VERSION "dbc-export 1 2026.26.6.5"

NS_ :

BS_:

BU_: BB GTW IDB TCU TCU2 UI UIS VCSEAT2L VCSEAT2R

BO_ 1056 UIS_log: 8 UIS
 SG_ UIS_logMux M : 0|32@1+ (1,0) [0|4294967295] "" Vector__XXX
 SG_ UIS_wifiTemperature m11 : 32|32@1+ (1,0) [0|4294967295] "" Vector__XXX
 SG_ UIS_wifiStackState m12 : 32|32@1+ (1,0) [0|4294967295] "" Vector__XXX
 SG_ UIS_wifiBars m14 : 32|32@1+ (1,0) [0|4294967295] "" Vector__XXX
 SG_ UIS_wifiAutoJoinLowRSSI m15 : 32|32@1+ (1,0) [0|1] "" Vector__XXX
 SG_ UIS_valetMode m26 : 32|32@1+ (1,0) [0|1] "" Vector__XXX
 SG_ UIS_uiQtCarUptime m27 : 32|32@1+ (1,0) [0|4294967295] "" Vector__XXX
 SG_ UIS_uiMeanFPS m29 : 32|32@1+ (1,0) [0|4294967295] "" Vector__XXX
 SG_ UIS_tunerVoltageOperation m36 : 32|32@1+ (1,0) [0|4294967295] "" Vector__XXX
 SG_ UIS_tunerVoltageAntenna2 m38 : 32|32@1+ (1,0) [0|4294967295] "" Vector__XXX
 SG_ UIS_tunerVoltageAntenna1 m39 : 32|32@1+ (1,0) [0|4294967295] "" Vector__XXX
 SG_ UIS_tunerCurrentAntenna2 m44 : 32|32@1+ (1,0) [0|4294967295] "" Vector__XXX
 SG_ UIS_tunerCurrentAntenna1 m45 : 32|32@1+ (1,0) [0|4294967295] "" Vector__XXX
 SG_ UIS_tegraModemManState m62 : 32|32@1+ (1,0) [0|4294967295] "" Vector__XXX
 SG_ UIS_systemWakeTime m63 : 32|32@1+ (1,0) [0|4294967295] "" Vector__XXX
 SG_ UIS_systemUptime m64 : 32|32@1+ (1,0) [0|4294967295] "" Vector__XXX
 SG_ UIS_suspensionGeofence m66 : 32|32@1+ (1,0) [0|1] "" Vector__XXX
 SG_ UIS_superchargePaymentNeeded m67 : 32|32@1+ (1,0) [0|4294967295] "" Vector__XXX
 SG_ UIS_sleepType m79 : 32|32@1+ (1,0) [0|4294967295] "" Vector__XXX
 SG_ UIS_sleepTime m80 : 32|32@1+ (1,0) [0|4294967295] "" Vector__XXX
 SG_ UIS_sleepState m81 : 32|32@1+ (1,0) [0|4294967295] "" Vector__XXX
 SG_ UIS_slackerLoginResult m83 : 32|32@1+ (1,0) [0|4294967295] "" Vector__XXX
 SG_ UIS_sentryState m89 : 32|32@1+ (1,0) [0|4294967295] "" Vector__XXX
 SG_ UIS_sentryNeedsNap m90 : 32|32@1+ (1,0) [0|4294967295] "" Vector__XXX
 SG_ UIS_sentryIncidentCount m91 : 32|32@1+ (1,0) [0|4294967295] "" Vector__XXX
 SG_ UIS_scheduledChargingMode m92 : 32|32@1+ (1,0) [0|4294967295] "" Vector__XXX
 SG_ UIS_scheduleChargeStartTime m93 : 32|32@1+ (1,0) [0|4294967295] "" Vector__XXX
 SG_ UIS_scheduleChargeEndTime m94 : 32|32@1+ (1,0) [0|4294967295] "" Vector__XXX
 SG_ UIS_remoteRequestType m96 : 32|32@1+ (1,0) [0|4294967295] "" Vector__XXX
 SG_ UIS_rearDisplayUserPresent m99 : 32|32@1+ (1,0) [0|1] "" Vector__XXX
 SG_ UIS_rearDisplayState m100 : 32|32@1+ (1,0) [0|4294967295] "" Vector__XXX
 SG_ UIS_powerManagerState m110 : 32|5@1+ (1,0) [0|31] "" Vector__XXX
 SG_ UIS_polytopiax8664MemUsage m111 : 32|32@1+ (1,0) [0|4294967295] "" Vector__XXX
 SG_ UIS_polytopiax8664CPUUsage m112 : 32|32@1+ (1,0) [0|4294967295] "" Vector__XXX
 SG_ UIS_navServiceError m157 : 32|32@1+ (1,0) [0|4294967295] "" Vector__XXX
 SG_ UIS_navAudioVolume m158 : 32|32@1+ (1,0) [0|4294967295] "" Vector__XXX
 SG_ UIS_muteNavVolume m159 : 32|32@1+ (1,0) [0|4294967295] "" Vector__XXX
 SG_ UIS_modemECallppAvail m171 : 32|32@1+ (1,0) [0|1] "" Vector__XXX
 SG_ UIS_modemBusyActive m172 : 32|32@1+ (1,0) [0|1] "" Vector__XXX
 SG_ UIS_mirrorGeofenceActive m173 : 32|32@1+ (1,0) [0|1] "" Vector__XXX
 SG_ UIS_mediaPlaybackStatus m176 : 32|32@1+ (1,0) [0|4294967295] "" Vector__XXX
 SG_ UIS_mediaNeedAuthToken m177 : 32|32@1+ (1,0) [0|1] "" Vector__XXX
 SG_ UIS_inSuperchargerGeofence m182 : 32|32@1+ (1,0) [0|1] "" Vector__XXX
 SG_ UIS_homelinkState m184 : 32|32@1+ (1,0) [0|4294967295] "" Vector__XXX
 SG_ UIS_headsetPairResult m197 : 32|32@1+ (1,0) [0|4294967295] "" Vector__XXX
 SG_ UIS_headsetConnectionState m198 : 32|32@1+ (1,0) [0|4294967295] "" Vector__XXX
 SG_ UIS_gpsmanagerMemUsage m212 : 32|32@1+ (1,0) [0|4294967295] "" Vector__XXX
 SG_ UIS_gpsmanagerCPUUsage m213 : 32|32@1+ (1,0) [0|4294967295] "" Vector__XXX
 SG_ UIS_featureSuperchargingEnabled m221 : 32|32@1+ (1,0) [0|4294967295] "" Vector__XXX
 SG_ UIS_dmRearTouchDeviceExists m234 : 32|32@1+ (1,0) [0|4294967295] "" Vector__XXX
 SG_ UIS_dmRearPowerState m235 : 32|32@1+ (1,0) [0|1] "" Vector__XXX
 SG_ UIS_dmRearLinkCheckOk m236 : 32|32@1+ (1,0) [0|1] "" Vector__XXX
 SG_ UIS_dmRearEnabled m237 : 32|32@1+ (1,0) [0|4294967295] "" Vector__XXX
 SG_ UIS_dmRearConnected m238 : 32|32@1+ (1,0) [0|4294967295] "" Vector__XXX
 SG_ UIS_dmRearBacklightDutyCycle m242 : 32|32@1+ (1,0) [0|4294967295] "" Vector__XXX
 SG_ UIS_dmRearBacklightDevExists m243 : 32|32@1+ (1,0) [0|1] "" Vector__XXX
 SG_ UIS_dmIcuPowerState m247 : 32|32@1+ (1,0) [0|1] "" Vector__XXX
 SG_ UIS_dmIcuLinkCheckOk m248 : 32|32@1+ (1,0) [0|1] "" Vector__XXX
 SG_ UIS_dmIcuEnabled m249 : 32|32@1+ (1,0) [0|4294967295] "" Vector__XXX
 SG_ UIS_dmIcuConnected m250 : 32|32@1+ (1,0) [0|4294967295] "" Vector__XXX
 SG_ UIS_dmIcuBacklightDutyCycle m254 : 32|32@1+ (1,0) [0|4294967295] "" Vector__XXX
 SG_ UIS_dmIcuBacklightDevExists m255 : 32|32@1+ (1,0) [0|1] "" Vector__XXX
 SG_ UIS_dmGatewayLinkWedged m260 : 32|32@1+ (1,0) [0|4294967295] "" Vector__XXX
 SG_ UIS_dmCenterTouchDeviceExists m262 : 32|32@1+ (1,0) [0|4294967295] "" Vector__XXX
 SG_ UIS_dmCenterPowerState m265 : 32|32@1+ (1,0) [0|1] "" Vector__XXX
 SG_ UIS_dmCenterOsdDisplayedState m266 : 32|32@1+ (1,0) [0|1] "" Vector__XXX
 SG_ UIS_dmCenterLinkCheckOk m271 : 32|32@1+ (1,0) [0|1] "" Vector__XXX
 SG_ UIS_dmCenterEnabled m272 : 32|32@1+ (1,0) [0|4294967295] "" Vector__XXX
 SG_ UIS_dmCenterConnected m273 : 32|32@1+ (1,0) [0|4294967295] "" Vector__XXX
 SG_ UIS_dmCenterBacklightPowerLevel m274 : 32|32@1+ (1,0) [0|4294967295] "" Vector__XXX
 SG_ UIS_dmCenterBacklightDutyCycle m277 : 32|32@1+ (1,0) [0|4294967295] "" Vector__XXX
 SG_ UIS_dmCenterBacklightDevExists m278 : 32|32@1+ (1,0) [0|1] "" Vector__XXX
 SG_ UIS_dmCenterBacklightControlDefe m279 : 32|32@1+ (1,0) [0|4294967295] "" Vector__XXX
 SG_ UIS_dgpuTemperature m285 : 32|32@1+ (1,0) [0|4294967295] "" Vector__XXX
 SG_ UIS_dashcamviewerMemUsage m287 : 32|32@1+ (1,0) [0|4294967295] "" Vector__XXX
 SG_ UIS_dashcamviewerCPUUsage m288 : 32|32@1+ (1,0) [0|4294967295] "" Vector__XXX
 SG_ UIS_dashcamStorageState m294 : 32|32@1+ (1,0) [0|4294967295] "" Vector__XXX
 SG_ UIS_dashcamStorageSentryMB m295 : 32|32@1+ (1,0) [0|4294967295] "" Vector__XXX
 SG_ UIS_dashcamStorageSavedMB m296 : 32|32@1+ (1,0) [0|4294967295] "" Vector__XXX
 SG_ UIS_dashcamStorageRecentMB m297 : 32|32@1+ (1,0) [0|4294967295] "" Vector__XXX
 SG_ UIS_dashcamStorageAvailableMB m298 : 32|32@1+ (1,0) [0|4294967295] "" Vector__XXX
 SG_ UIS_dashcamState m299 : 32|32@1+ (1,0) [0|4294967295] "" Vector__XXX
 SG_ UIS_cpuTemperature m308 : 32|32@1+ (1,0) [0|4294967295] "" Vector__XXX
 SG_ UIS_clusterMemUsage m321 : 32|32@1+ (1,0) [0|4294967295] "" Vector__XXX
 SG_ UIS_clusterDisplayState m326 : 32|32@1+ (1,0) [0|4294967295] "" Vector__XXX
 SG_ UIS_clusterCPUUsage m327 : 32|32@1+ (1,0) [0|4294967295] "" Vector__XXX
 SG_ UIS_chargeOnSolarNoChargeReason m330 : 32|32@1+ (1,0) [0|4294967295] "" Vector__XXX
 SG_ UIS_chargeLocationId m331 : 32|32@1+ (1,0) [0|4294967295] "" Vector__XXX
 SG_ UIS_centerDisplayState m334 : 32|32@1+ (1,0) [0|4294967295] "" Vector__XXX
 SG_ UIS_centerDisplayEvent m335 : 32|32@1+ (1,0) [0|4294967295] "" Vector__XXX
 SG_ UIS_cellularLinkManagerState m340 : 32|32@1+ (1,0) [0|4294967295] "" Vector__XXX
 SG_ UIS_cellularConnectivityStatus m341 : 32|32@1+ (1,0) [0|1] "" Vector__XXX
 SG_ UIS_carAssistState m369 : 32|32@1+ (1,0) [0|4294967295] "" Vector__XXX
 SG_ UIS_carAssistSessionCount m370 : 32|32@1+ (1,0) [0|4294967295] "" Vector__XXX
 SG_ UIS_carAssistMicMuted m371 : 32|32@1+ (1,0) [0|1] "" Vector__XXX
 SG_ UIS_carAssistMicAlsaRms m372 : 32|32@1+ (1,0) [0|4294967295] "" Vector__XXX
 SG_ UIS_carAssistErrorCode m373 : 32|32@1+ (1,0) [0|4294967295] "" Vector__XXX
 SG_ UIS_cameraSelectableRenderState m374 : 32|32@1+ (1,0) [0|4294967295] "" Vector__XXX
 SG_ UIS_cameraSelectablePipeline m375 : 32|32@1+ (1,0) [0|4294967295] "" Vector__XXX
 SG_ UIS_cameraSelectablePacketState m376 : 32|32@1+ (1,0) [0|4294967295] "" Vector__XXX
 SG_ UIS_cameraRearViewRenderState m378 : 32|32@1+ (1,0) [0|4294967295] "" Vector__XXX
 SG_ UIS_cameraRearViewPacketState m381 : 32|32@1+ (1,0) [0|4294967295] "" Vector__XXX
 SG_ UIS_cameraRRepeaterStreamMissing m382 : 32|32@1+ (1,0) [0|1] "" Vector__XXX
 SG_ UIS_cameraRRepeaterRenderState m383 : 32|32@1+ (1,0) [0|4294967295] "" Vector__XXX
 SG_ UIS_cameraRRepeaterPopup m384 : 32|32@1+ (1,0) [0|1] "" Vector__XXX
 SG_ UIS_cameraRRepeaterPipeline m385 : 32|32@1+ (1,0) [0|4294967295] "" Vector__XXX
 SG_ UIS_cameraRRepeaterPacketState m386 : 32|32@1+ (1,0) [0|4294967295] "" Vector__XXX
 SG_ UIS_cameraRDownwardRenderState m390 : 32|32@1+ (1,0) [0|4294967295] "" Vector__XXX
 SG_ UIS_cameraRDownwardPacketState m392 : 32|32@1+ (1,0) [0|4294967295] "" Vector__XXX
 SG_ UIS_cameraLRepeaterStreamMissing m393 : 32|32@1+ (1,0) [0|1] "" Vector__XXX
 SG_ UIS_cameraLRepeaterRenderState m394 : 32|32@1+ (1,0) [0|4294967295] "" Vector__XXX
 SG_ UIS_cameraLRepeaterPopup m395 : 32|32@1+ (1,0) [0|1] "" Vector__XXX
 SG_ UIS_cameraLRepeaterPipeline m396 : 32|32@1+ (1,0) [0|4294967295] "" Vector__XXX
 SG_ UIS_cameraLRepeaterPacketState m397 : 32|32@1+ (1,0) [0|4294967295] "" Vector__XXX
 SG_ UIS_cameraLDownwardRenderState m401 : 32|32@1+ (1,0) [0|4294967295] "" Vector__XXX
 SG_ UIS_cameraLDownwardPacketState m403 : 32|32@1+ (1,0) [0|4294967295] "" Vector__XXX
 SG_ UIS_cameraFrontRenderState m405 : 32|32@1+ (1,0) [0|4294967295] "" Vector__XXX
 SG_ UIS_cameraFrontPacketState m408 : 32|32@1+ (1,0) [0|4294967295] "" Vector__XXX
 SG_ UIS_cameraBackupStreamMissing m410 : 32|32@1+ (1,0) [0|1] "" Vector__XXX
 SG_ UIS_cameraBackupRenderState m411 : 32|32@1+ (1,0) [0|4294967295] "" Vector__XXX
 SG_ UIS_cameraBackupPopup m412 : 32|32@1+ (1,0) [0|1] "" Vector__XXX
 SG_ UIS_cameraBackupPipeline m413 : 32|32@1+ (1,0) [0|4294967295] "" Vector__XXX
 SG_ UIS_cameraBackupPacketState m414 : 32|32@1+ (1,0) [0|4294967295] "" Vector__XXX
 SG_ UIS_cameraBackupFramerate m418 : 32|32@1+ (1,0) [0|4294967295] "" Vector__XXX
 SG_ UIS_boardTemperature m424 : 32|32@1+ (1,0) [0|4294967295] "" Vector__XXX
 SG_ UIS_bluetoothState m425 : 32|32@1+ (1,0) [0|4294967295] "" Vector__XXX
 SG_ UIS_bluetoothStackState m426 : 32|32@1+ (1,0) [0|4294967295] "" Vector__XXX
 SG_ UIS_bluetoothStackRearState m427 : 32|32@1+ (1,0) [0|4294967295] "" Vector__XXX
 SG_ UIS_bluetoothPairResult m428 : 32|32@1+ (1,0) [0|4294967295] "" Vector__XXX
 SG_ UIS_bluetoothMemUsage m429 : 32|32@1+ (1,0) [0|4294967295] "" Vector__XXX
 SG_ UIS_bluetoothConnectionState m430 : 32|32@1+ (1,0) [0|4294967295] "" Vector__XXX
 SG_ UIS_bluetoothCPUUsage m431 : 32|32@1+ (1,0) [0|4294967295] "" Vector__XXX
 SG_ UIS_bluetoothAutoconnectAttempts m432 : 32|32@1+ (1,0) [0|4294967295] "" Vector__XXX
 SG_ UIS_bluetoothAutoconnectActive m433 : 32|32@1+ (1,0) [0|4294967295] "" Vector__XXX
 SG_ UIS_bluetoothAutoConnectionState m434 : 32|32@1+ (1,0) [0|4294967295] "" Vector__XXX
 SG_ UIS_backlightUserRequest m439 : 32|32@1+ (1,0) [0|4294967295] "" Vector__XXX
 SG_ UIS_audioVolumeLevel m440 : 32|32@1+ (1,0) [0|4294967295] "" Vector__XXX
 SG_ UIS_audioType m441 : 32|32@1+ (1,0) [0|4294967295] "" Vector__XXX
 SG_ UIS_audioState m442 : 32|32@1+ (1,0) [0|4294967295] "" Vector__XXX
 SG_ UIS_audioSource m443 : 32|32@1+ (1,0) [0|4294967295] "" Vector__XXX
 SG_ UIS_audioPWSGain m444 : 32|32@1+ (1,0) [0|4294967295] "" Vector__XXX
 SG_ UIS_audioMediaPlaying m445 : 32|32@1+ (1,0) [0|4294967295] "" Vector__XXX
 SG_ UIS_audioMediaBrowsing m446 : 32|32@1+ (1,0) [0|4294967295] "" Vector__XXX
 SG_ UIS_audioA2BRediscoveryCount m447 : 32|32@1+ (1,0) [0|4294967295] "" Vector__XXX
 SG_ UIS_apeHardwareMinorVersion m448 : 32|32@1+ (1,0) [0|4294967295] "" Vector__XXX
 SG_ UIS_activeAppView m450 : 32|32@1+ (1,0) [0|4294967295] "" Vector__XXX
 SG_ UIS_CamViewerServiceEnabled m451 : 32|32@1+ (1,0) [0|4294967295] "" Vector__XXX

BO_ 979 UI_airbagCutoffStatus: 1 UI
 SG_ UI_airbagCutoffSwState : 0|2@1+ (1,0) [0|3] "" Vector__XXX

BO_ 1279 UI_energyConsumptionInfo: 8 UI
 SG_ UI_energyConsumptionInfoIndex M : 0|5@1+ (1,0) [0|31] "" Vector__XXX
 SG_ UI_energyLossTotal_epa m0 : 16|16@1- (1,0) [-32768|32767] "Wh" Vector__XXX
 SG_ UI_energyLossDriving_epa m0 : 32|16@1- (1,0) [-32768|32767] "Wh" Vector__XXX
 SG_ UI_energyLossClimate_epa m0 : 48|16@1- (1,0) [-32768|32767] "Wh" Vector__XXX
 SG_ UI_energyLossBattCond_epa m1 : 16|16@1- (1,0) [-32768|32767] "Wh" Vector__XXX
 SG_ UI_energyLossElevation_epa m1 : 32|16@1- (1,0) [-32768|32767] "Wh" Vector__XXX
 SG_ UI_energyLossAcc_epa m1 : 48|16@1- (1,0) [-32768|32767] "Wh" Vector__XXX
 SG_ UI_energyLossTotalSinceCharge_ep m2 : 16|16@1- (1,0) [-32768|32767] "Wh" Vector__XXX
 SG_ UI_energyLossDrivingSinceCharge_ m2 : 32|16@1- (1,0) [-32768|32767] "Wh" Vector__XXX
 SG_ UI_energyLossClimateSinceCharge_ m2 : 48|16@1- (1,0) [-32768|32767] "Wh" Vector__XXX
 SG_ UI_energyLossBattCondSinceCharge m3 : 16|16@1- (1,0) [-32768|32767] "Wh" Vector__XXX
 SG_ UI_energyLossElevationSinceCharg m3 : 32|16@1- (1,0) [-32768|32767] "Wh" Vector__XXX
 SG_ UI_energyLossAccSinceCharge_epa m3 : 48|16@1- (1,0) [-32768|32767] "Wh" Vector__XXX
 SG_ UI_energyLossTotalSinceTripStart m4 : 16|16@1- (1,0) [-32768|32767] "Wh" Vector__XXX
 SG_ UI_energyLossDrivingSinceTripSta m4 : 32|16@1- (1,0) [-32768|32767] "Wh" Vector__XXX
 SG_ UI_energyLossClimateSinceTripSta m4 : 48|16@1- (1,0) [-32768|32767] "Wh" Vector__XXX
 SG_ UI_energyLossBattCondSinceTripSt m5 : 16|16@1- (1,0) [-32768|32767] "Wh" Vector__XXX
 SG_ UI_energyLossElevationSinceTripS m5 : 32|16@1- (1,0) [-32768|32767] "Wh" Vector__XXX
 SG_ UI_energyLossAccSinceTripStart m5 : 48|16@1- (1,0) [-32768|32767] "Wh" Vector__XXX
 SG_ UI_energyDeltaTotal_epa m6 : 16|16@1- (1,0) [-32768|32767] "Wh" Vector__XXX
 SG_ UI_energyDeltaDriving_epa m6 : 32|16@1- (1,0) [-32768|32767] "Wh" Vector__XXX
 SG_ UI_energyDeltaClimate_epa m6 : 48|16@1- (1,0) [-32768|32767] "Wh" Vector__XXX
 SG_ UI_energyDeltaBattCond_epa m7 : 16|16@1- (1,0) [-32768|32767] "Wh" Vector__XXX
 SG_ UI_energyDeltaElevation_epa m7 : 32|16@1- (1,0) [-32768|32767] "Wh" Vector__XXX
 SG_ UI_energyDeltaAcc_epa m7 : 48|16@1- (1,0) [-32768|32767] "Wh" Vector__XXX
 SG_ UI_uiDeltaOffsetTotal_epa m8 : 16|16@1- (1,0) [-32768|32767] "Wh" Vector__XXX
 SG_ UI_uiDeltaOffsetDriving_epa m8 : 32|16@1- (1,0) [-32768|32767] "Wh" Vector__XXX
 SG_ UI_uiDeltaOffsetClimate_epa m8 : 48|16@1- (1,0) [-32768|32767] "Wh" Vector__XXX
 SG_ UI_uiDeltaOffsetBattCond_epa m9 : 16|16@1- (1,0) [-32768|32767] "Wh" Vector__XXX
 SG_ UI_uiDeltaOffsetElevation_epa m9 : 32|16@1- (1,0) [-32768|32767] "Wh" Vector__XXX
 SG_ UI_uiDeltaOffsetAcc_epa m9 : 48|16@1- (1,0) [-32768|32767] "Wh" Vector__XXX
 SG_ UI_rawToUiEnergyRatio_epa m10 : 8|8@1+ (0.01,0) [0|2.55] "-" Vector__XXX
 SG_ UI_driveDistance_epa m10 : 16|16@1+ (0.01,0) [0|655.35] "miles" Vector__XXX
 SG_ UI_energyDeltaTotalSinceCharge_e m11 : 16|16@1- (1,0) [-32768|32767] "Wh" Vector__XXX
 SG_ UI_energyDeltaDrivingSinceCharge m11 : 32|16@1- (1,0) [-32768|32767] "Wh" Vector__XXX
 SG_ UI_energyDeltaClimateSinceCharge m11 : 48|16@1- (1,0) [-32768|32767] "Wh" Vector__XXX
 SG_ UI_energyDeltaBattCondSinceCharg m12 : 16|16@1- (1,0) [-32768|32767] "Wh" Vector__XXX
 SG_ UI_energyDeltaElevationSinceChar m12 : 32|16@1- (1,0) [-32768|32767] "Wh" Vector__XXX
 SG_ UI_energyDeltaAccSinceCharge_epa m12 : 48|16@1- (1,0) [-32768|32767] "Wh" Vector__XXX
 SG_ UI_uiDeltaOffsetTotalSinceCharge m13 : 16|16@1- (1,0) [-32768|32767] "Wh" Vector__XXX
 SG_ UI_uiDeltaOffsetDrivingSinceChar m13 : 32|16@1- (1,0) [-32768|32767] "Wh" Vector__XXX
 SG_ UI_uiDeltaOffsetClimateSinceChar m13 : 48|16@1- (1,0) [-32768|32767] "Wh" Vector__XXX
 SG_ UI_uiDeltaOffsetBattCondSinceCha m14 : 16|16@1- (1,0) [-32768|32767] "Wh" Vector__XXX
 SG_ UI_uiDeltaOffsetElevationSinceCh m14 : 32|16@1- (1,0) [-32768|32767] "Wh" Vector__XXX
 SG_ UI_uiDeltaOffsetAccSinceCharge_e m14 : 48|16@1- (1,0) [-32768|32767] "Wh" Vector__XXX
 SG_ UI_rawToUiEnergyRatioSinceCharge m15 : 8|8@1+ (0.01,0) [0|2.55] "-" Vector__XXX
 SG_ UI_driveDistanceSinceCharge_epa m15 : 16|16@1+ (0.01,0) [0|655.35] "miles" Vector__XXX
 SG_ UI_energyDeltaTotalSinceTripStar m16 : 16|16@1- (1,0) [-32768|32767] "Wh" Vector__XXX
 SG_ UI_energyDeltaDrivingSinceTripSt m16 : 32|16@1- (1,0) [-32768|32767] "Wh" Vector__XXX
 SG_ UI_energyDeltaClimateSinceTripSt m16 : 48|16@1- (1,0) [-32768|32767] "Wh" Vector__XXX
 SG_ UI_energyDeltaBattCondSinceTripS m17 : 16|16@1- (1,0) [-32768|32767] "Wh" Vector__XXX
 SG_ UI_energyDeltaElevationSinceTrip m17 : 32|16@1- (1,0) [-32768|32767] "Wh" Vector__XXX
 SG_ UI_energyDeltaAccSinceTripStart m17 : 48|16@1- (1,0) [-32768|32767] "Wh" Vector__XXX
 SG_ UI_uiDeltaOffsetTotalSinceTripSt m18 : 16|16@1- (1,0) [-32768|32767] "Wh" Vector__XXX
 SG_ UI_uiDeltaOffsetDrivingSinceTrip m18 : 32|16@1- (1,0) [-32768|32767] "Wh" Vector__XXX
 SG_ UI_uiDeltaOffsetClimateSinceTrip m18 : 48|16@1- (1,0) [-32768|32767] "Wh" Vector__XXX
 SG_ UI_uiDeltaOffsetBattCondSinceTri m19 : 16|16@1- (1,0) [-32768|32767] "Wh" Vector__XXX
 SG_ UI_uiDeltaOffsetElevationSinceTr m19 : 32|16@1- (1,0) [-32768|32767] "Wh" Vector__XXX
 SG_ UI_uiDeltaOffsetAccSinceTripStar m19 : 48|16@1- (1,0) [-32768|32767] "Wh" Vector__XXX
 SG_ UI_rawToUiEnergyRatioSinceTripSt m20 : 8|8@1+ (0.01,0) [0|2.55] "-" Vector__XXX
 SG_ UI_driveDistanceSinceTripStart m20 : 16|16@1+ (0.01,0) [0|655.35] "miles" Vector__XXX
 SG_ UI_trailerMass m21 : 16|16@1+ (1,0) [0|65535] "kg" Vector__XXX

BO_ 666 UI_seatControl: 3 UI
 SG_ UI_seatControlIndex M : 0|2@1+ (1,0) [0|3] "" Vector__XXX
 SG_ UI_3RSeatChildLock m0 : 2|2@1+ (1,0) [0|3] "" Vector__XXX
 SG_ UI_left3RowSeatAdjustmentRequest m0 : 8|3@1+ (1,0) [0|7] "" Vector__XXX
 SG_ UI_right3RowSeatAdjustmentReques m0 : 11|3@1+ (1,0) [0|7] "" Vector__XXX
 SG_ UI_2RLeftSeatFanReq m0 : 14|2@1+ (1,0) [0|3] "" Vector__XXX
 SG_ UI_2RRightSeatFanReq m0 : 16|2@1+ (1,0) [0|3] "" Vector__XXX
 SG_ UI_seatChoreographyStopRequest m0 : 20|1@1+ (1,0) [0|1] "" Vector__XXX

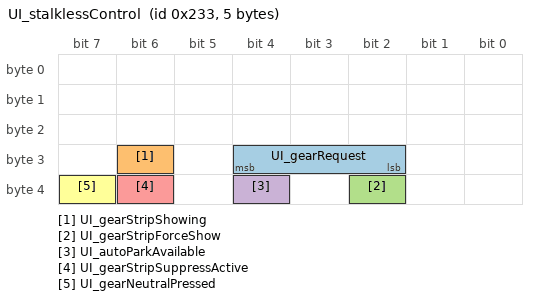
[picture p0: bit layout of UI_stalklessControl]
BO_ 563 UI_stalklessControl: 5 UI
 SG_ UI_gearRequest : 26|3@1+ (1,0) [1|7] "" Vector__XXX
 SG_ UI_gearStripShowing : 30|1@1+ (1,0) [0|1] "" Vector__XXX
 SG_ UI_gearStripForceShow : 34|1@1+ (1,0) [0|1] "" Vector__XXX
 SG_ UI_autoParkAvailable : 36|1@1+ (1,0) [0|1] "" Vector__XXX
 SG_ UI_gearStripSuppressActive : 38|1@1+ (1,0) [0|1] "" Vector__XXX
 SG_ UI_gearNeutralPressed : 39|1@1+ (1,0) [0|1] "" Vector__XXX

BO_ 986 UI_status3: 1 UI
 SG_ UI_wifiRegDomain : 0|7@1+ (1,0) [0|127] "" Vector__XXX
 SG_ UI_wifiTethered : 7|1@1+ (1,0) [0|1] "" Vector__XXX

BO_ 661 UI_systemMonitor: 8 UI
 SG_ UI_systemMonitorIndex M : 0|1@1+ (1,0) [0|1] "" Vector__XXX
 SG_ UI_SystemMemUsage m0 : 8|16@1+ (1,0) [0|65535] "MB" Vector__XXX
 SG_ UI_QtCarMemUsage m0 : 24|16@1+ (1,0) [0|65535] "MB" Vector__XXX
 SG_ UI_QtCarCPUUsage m0 : 40|7@1+ (1,0) [0|127] "%" Vector__XXX
 SG_ UI_SystemCPUUsage m0 : 48|7@1+ (1,0) [0|127] "%" Vector__XXX

BO_ 1263 UI_tripPlannerInfo: 5 UI
 SG_ UI_fwHeatOnNavArrivalSOE : 0|10@1+ (0.1,0) [0|100] "%" Vector__XXX
 SG_ UI_voyagerHeatOnNavArrivalSOE : 16|10@1+ (0.1,0) [0|100] "%" Vector__XXX

BO_ 139 UI_tripPlanning2: 6 UI
 SG_ UI_maxSpeedToReachDestination : 0|16@1+ (0.01,0) [0|655.34] "m/s" Vector__XXX
 SG_ UI_timeToDestination : 32|16@1+ (1,0) [0|65534] "s" Vector__XXX

BO_ 1173 UI_tripPlanning3: 8 UI
 SG_ UI_predictedEnergy : 0|16@1- (0.01,0) [-327.67|327.67] "kWh" Vector__XXX
 SG_ UI_hindsightEnergy : 32|16@1- (0.01,0) [-327.67|327.67] "kWh" Vector__XXX

BO_ 764 VCSEAT2L_seatStatus: 8 VCSEAT2L
 SG_ VCSEAT2L_row2SeatStatusIndex M : 0|2@1+ (1,0) [0|3] "" Vector__XXX
 SG_ VCSEAT2L_seatTrackPosReal m1 : 4|12@1- (1,0) [-2048|2047] "mm" Vector__XXX
 SG_ VCSEAT2L_seatTrackPosOffset m1 : 16|12@1- (1,0) [-2048|2047] "mm" Vector__XXX
 SG_ VCSEAT2L_seatReclineState m1 : 28|4@1+ (1,0) [0|14] "" Vector__XXX
 SG_ VCSEAT2L_seatReclineCalibrated m1 : 32|1@1+ (1,0) [0|1] "" Vector__XXX
 SG_ VCSEAT2L_seatReclinePositionStat m1 : 33|3@1+ (1,0) [0|7] "" Vector__XXX
 SG_ VCSEAT2L_seatReclineAbsPosS_0001 m1 : 36|12@1- (0.1,0) [-204.8|204.7] "deg" Vector__XXX
 SG_ VCSEAT2L_seatReclineAbsPosSwitch m1 : 48|2@1+ (1,0) [1|3] "" Vector__XXX
 SG_ VCSEAT2L_seatReclineFoldAllowed m1 : 50|1@1+ (1,0) [0|1] "" Vector__XXX
 SG_ VCSEAT2L_seatReclineUnfoldAllowe m1 : 51|1@1+ (1,0) [0|1] "" Vector__XXX
 SG_ VCSEAT2L_seatReclineAdjustmentAl m1 : 52|1@1+ (1,0) [0|1] "" Vector__XXX
 SG_ VCSEAT2L_seat1RClashAvoidanceBlo m1 : 53|3@1+ (1,0) [0|7] "" Vector__XXX
 SG_ VCSEAT2L_seat1RClashAvoidanceSta m1 : 56|2@1+ (1,0) [0|3] "" Vector__XXX
 SG_ VCSEAT2L_seatReclineChoreoBlocke m1 : 58|1@1+ (1,0) [0|1] "" Vector__XXX
 SG_ VCSEAT2L_seatReclineNextToggleDi m1 : 59|2@1+ (1,0) [0|3] "" Vector__XXX

BO_ 1986 VCSEAT2L_seatStatus2: 8 VCSEAT2L
 SG_ VCSEAT2L_seatStatus2Index M : 0|3@1+ (1,0) [0|7] "" Vector__XXX
 SG_ VCSEAT2L_choreography2RState m4 : 4|2@1+ (1,0) [0|3] "" Vector__XXX
 SG_ VCSEAT2L_choreography3RState m4 : 7|2@1+ (1,0) [0|3] "" Vector__XXX
 SG_ VCSEAT2L_choreography1RIsAllowed m4 : 10|1@1+ (1,0) [0|1] "" Vector__XXX
 SG_ VCSEAT2L_choreography2RIsAllowed m4 : 11|1@1+ (1,0) [0|1] "" Vector__XXX
 SG_ VCSEAT2L_choreography1RTrackVelo m4 : 12|3@1+ (1,0) [0|7] "" Vector__XXX
 SG_ VCSEAT2L_choreography1RBackrestV m4 : 15|3@1+ (1,0) [0|7] "" Vector__XXX
 SG_ VCSEAT2L_choreography2RTrackVelo m4 : 18|3@1+ (1,0) [0|7] "" Vector__XXX
 SG_ VCSEAT2L_choreography2RBackrestV m4 : 21|3@1+ (1,0) [0|7] "" Vector__XXX
 SG_ VCSEAT2L_choreography3RBackrestV m4 : 24|3@1+ (1,0) [0|7] "" Vector__XXX
 SG_ VCSEAT2L_choreographyState m4 : 27|4@1+ (1,0) [0|15] "" Vector__XXX
 SG_ VCSEAT2L_choreographyCollisionPa m4 : 32|3@1+ (1,0) [0|7] "" Vector__XXX
 SG_ VCSEAT2L_2rMovingForChoreography m4 : 35|1@1+ (1,0) [0|1] "" Vector__XXX

BO_ 746 VCSEAT2R_seatStatus2: 8 VCSEAT2R
 SG_ VCSEAT2R_seatStatus2Index M : 0|3@1+ (1,0) [0|7] "" Vector__XXX
 SG_ VCSEAT2R_choreography2RState m4 : 4|2@1+ (1,0) [0|3] "" Vector__XXX
 SG_ VCSEAT2R_choreography3RState m4 : 7|2@1+ (1,0) [0|3] "" Vector__XXX
 SG_ VCSEAT2R_choreography1RIsAllowed m4 : 10|1@1+ (1,0) [0|1] "" Vector__XXX
 SG_ VCSEAT2R_choreography2RIsAllowed m4 : 11|1@1+ (1,0) [0|1] "" Vector__XXX
 SG_ VCSEAT2R_choreography1RTrackVelo m4 : 12|3@1+ (1,0) [0|7] "" Vector__XXX
 SG_ VCSEAT2R_choreography1RBackrestV m4 : 15|3@1+ (1,0) [0|7] "" Vector__XXX
 SG_ VCSEAT2R_choreography2RTrackVelo m4 : 18|3@1+ (1,0) [0|7] "" Vector__XXX
 SG_ VCSEAT2R_choreography2RBackrestV m4 : 21|3@1+ (1,0) [0|7] "" Vector__XXX
 SG_ VCSEAT2R_choreography3RBackrestV m4 : 24|3@1+ (1,0) [0|7] "" Vector__XXX
 SG_ VCSEAT2R_choreographyState m4 : 27|4@1+ (1,0) [0|15] "" Vector__XXX
 SG_ VCSEAT2R_choreographyCollisionPa m4 : 32|3@1+ (1,0) [0|7] "" Vector__XXX
 SG_ VCSEAT2R_2rMovingForChoreography m4 : 35|1@1+ (1,0) [0|1] "" Vector__XXX

BO_TX_BU_ 1056 : UIS;
BO_TX_BU_ 979 : UI;
BO_TX_BU_ 1279 : UI;
BO_TX_BU_ 666 : UI;
BO_TX_BU_ 563 : UI;
BO_TX_BU_ 986 : UI;
BO_TX_BU_ 661 : UI;
BO_TX_BU_ 1263 : UI;
BO_TX_BU_ 139 : UI;
BO_TX_BU_ 1173 : UI;
BO_TX_BU_ 764 : VCSEAT2L;
BO_TX_BU_ 1986 : VCSEAT2L;
BO_TX_BU_ 746 : VCSEAT2R;
CM_ BO_ 1056 "UIS ECU message: log";
CM_ SG_ 1056 UIS_logMux "UIS ECU: log mux";
CM_ SG_ 1056 UIS_wifiTemperature "Current temperature reported for wifi";
CM_ SG_ 1056 UIS_wifiStackState "WiFi stack state description";
CM_ SG_ 1056 UIS_wifiBars "WiFi bars for connected network";
CM_ SG_ 1056 UIS_wifiAutoJoinLowRSSI "Indicates an attempt to auto-join a known network with low Received Signal Strength Indicator (RSSI).";
CM_ SG_ 1056 UIS_valetMode "UI Valet Mode state";
CM_ SG_ 1056 UIS_uiQtCarUptime "Touchscreen UI software uptime";
CM_ SG_ 1056 UIS_uiMeanFPS "UI mean frames per second over a 60s period";
CM_ SG_ 1056 UIS_tunerVoltageOperation "Radio tuner operating voltage (mV)";
CM_ SG_ 1056 UIS_tunerVoltageAntenna2 "Radio tuner voltage (mV) for antenna 2";
CM_ SG_ 1056 UIS_tunerVoltageAntenna1 "Radio tuner voltage (mV) for antenna 1";
CM_ SG_ 1056 UIS_tunerCurrentAntenna2 "Radio tuner current (mA) for antenna 2";
CM_ SG_ 1056 UIS_tunerCurrentAntenna1 "Radio tuner current (mA) for antenna 1";
CM_ SG_ 1056 UIS_tegraModemManState "Tegra Cellular Modem Manager state";
CM_ SG_ 1056 UIS_systemWakeTime "Length of time since wake or boot if UI has not slept (seconds)";
CM_ SG_ 1056 UIS_systemUptime "Reports the system uptime duration.";
CM_ SG_ 1056 UIS_suspensionGeofence "Status of suspension geofence add or remove";
CM_ SG_ 1056 UIS_superchargePaymentNeeded "Reports that Supercharging payment is needed.";
CM_ SG_ 1056 UIS_sleepType "Reports the system sleep type.";
CM_ SG_ 1056 UIS_sleepTime "Reports the system sleep duration.";
CM_ SG_ 1056 UIS_sleepState "Reports the system sleep state.";
CM_ SG_ 1056 UIS_slackerLoginResult "Reports Slacker Media login events";
CM_ SG_ 1056 UIS_sentryState "Sentry Mode state";
CM_ SG_ 1056 UIS_sentryNeedsNap "Sentry Mode sleep indicator, max uptime reached";
CM_ SG_ 1056 UIS_sentryIncidentCount "Sentry Mode incident count, initializes to 0";
CM_ SG_ 1056 UIS_scheduledChargingMode "Scheduled charging mode";
CM_ SG_ 1056 UIS_scheduleChargeStartTime "Reports the scheduled charging start date time in MMDDHHMM format.";
CM_ SG_ 1056 UIS_scheduleChargeEndTime "Reports the scheduled charging end date time in MMDDHHMM format.";
CM_ SG_ 1056 UIS_remoteRequestType "Reports the signed remote request type sent to vehicle, excluding closures and start requests.";
CM_ SG_ 1056 UIS_rearDisplayUserPresent "Indicates if a user is present in the rear seat based on seat occupancy and rear display usage";
CM_ SG_ 1056 UIS_rearDisplayState "Reports the rear display state.";
CM_ SG_ 1056 UIS_powerManagerState "UI power manager state signal; raw 18 = signal not available (SNA)";
CM_ SG_ 1056 UIS_polytopiax8664MemUsage "polytopiax8664's Resident Memory usage in MB";
CM_ SG_ 1056 UIS_polytopiax8664CPUUsage "polytopiax8664's CPU usage in CPU usage %";
CM_ SG_ 1056 UIS_navServiceError "Reports the value of the navigation service error.";
CM_ SG_ 1056 UIS_navAudioVolume "Navigation audio volume level";
CM_ SG_ 1056 UIS_muteNavVolume "Mute state of the navigation audio";
CM_ SG_ 1056 UIS_modemECallppAvail "Reports whether eCall++ is enabled and is running on Telematics Control Unit (TCU).";
CM_ SG_ 1056 UIS_modemBusyActive "Reports whether the modem busy logic is requested to be active on the modem application processor.";
CM_ SG_ 1056 UIS_mirrorGeofenceActive "Folding mirror geofence active status";
CM_ SG_ 1056 UIS_mediaPlaybackStatus "Media Current Playback Status";
CM_ SG_ 1056 UIS_mediaNeedAuthToken "Indicates whether the media system needs a new authentication token.";
CM_ SG_ 1056 UIS_inSuperchargerGeofence "Vehicle inside Supercharger Geofence";
CM_ SG_ 1056 UIS_homelinkState "State of Homelink sate machine";
CM_ SG_ 1056 UIS_headsetPairResult "Bluetooth headset pairing result";
CM_ SG_ 1056 UIS_headsetConnectionState "Bluetooth headset connection state";
CM_ SG_ 1056 UIS_gpsmanagerMemUsage "gpsManager's Resident Memory usage in MB";
CM_ SG_ 1056 UIS_gpsmanagerCPUUsage "gpsManager's CPU usage in CPU usage %";
CM_ SG_ 1056 UIS_featureSuperchargingEnabled "Reports the Supercharging enabled feature status.";
CM_ SG_ 1056 UIS_dmRearTouchDeviceExists "Reports status of rear display power state.";
CM_ SG_ 1056 UIS_dmRearPowerState "Logs rear display power state status";
CM_ SG_ 1056 UIS_dmRearLinkCheckOk "Logs whether rear display-hardware-init was successful";
CM_ SG_ 1056 UIS_dmRearEnabled "Rear display is enabled";
CM_ SG_ 1056 UIS_dmRearConnected "Rear display is connected";
CM_ SG_ 1056 UIS_dmRearBacklightDutyCycle "Logs rear backlight duty cycle status";
CM_ SG_ 1056 UIS_dmRearBacklightDevExists "Logs whether rear backlight device exists and was successfully detected";
CM_ SG_ 1056 UIS_dmIcuPowerState "Logs cluster display power state status";
CM_ SG_ 1056 UIS_dmIcuLinkCheckOk "Logs whether cluster display-hardware-init was successful";
CM_ SG_ 1056 UIS_dmIcuEnabled "Cluster display is enabled";
CM_ SG_ 1056 UIS_dmIcuConnected "Cluster display is connected";
CM_ SG_ 1056 UIS_dmIcuBacklightDutyCycle "Logs cluster backlight duty cycle status";
CM_ SG_ 1056 UIS_dmIcuBacklightDevExists "Logs whether cluster backlight device exists and was successfully detected";
CM_ SG_ 1056 UIS_dmGatewayLinkWedged "Indicates whether the center display gateway link is stuck.";
CM_ SG_ 1056 UIS_dmCenterTouchDeviceExists "Detects whether the center display touch input device is present.";
CM_ SG_ 1056 UIS_dmCenterPowerState "Logs center display power state status";
CM_ SG_ 1056 UIS_dmCenterOsdDisplayedState "Reports the center display On-Screen Display (OSD) shown state.";
CM_ SG_ 1056 UIS_dmCenterLinkCheckOk "Logs whether center display-hardware-init was successful";
CM_ SG_ 1056 UIS_dmCenterEnabled "Center display is enabled";
CM_ SG_ 1056 UIS_dmCenterConnected "Center display is connected";
CM_ SG_ 1056 UIS_dmCenterBacklightPowerLevel "Logs backlight power level for center display";
CM_ SG_ 1056 UIS_dmCenterBacklightDutyCycle "Logs center backlight duty cycle status";
CM_ SG_ 1056 UIS_dmCenterBacklightDevExists "Logs whether center backlight device exists and was successfully detected";
CM_ SG_ 1056 UIS_dmCenterBacklightControlDefe "Indicates whether the center display backlight request to the gateway was deferred to the User Datagram Protocol Application Programming Interface (UDP API) or converged within 1 second.";
CM_ SG_ 1056 UIS_dgpuTemperature "Current temperature reported for dgpu";
CM_ SG_ 1056 UIS_dashcamviewerMemUsage "dashcamViewer's Resident Memory usage in MB";
CM_ SG_ 1056 UIS_dashcamviewerCPUUsage "dashcamViewer's CPU usage in CPU usage %";
CM_ SG_ 1056 UIS_dashcamStorageState "Internal state of the dashcam storage";
CM_ SG_ 1056 UIS_dashcamStorageSentryMB "Dashcam USB storage used by Sentry Clips in MB";
CM_ SG_ 1056 UIS_dashcamStorageSavedMB "Dashcam USB storage used by Saved Clips in MB";
CM_ SG_ 1056 UIS_dashcamStorageRecentMB "Dashcam USB storage used by Recent Clips in MB";
CM_ SG_ 1056 UIS_dashcamStorageAvailableMB "Dashcam USB storage that is Available in MB";
CM_ SG_ 1056 UIS_dashcamState "Internal state for the dashcam state machine";
CM_ SG_ 1056 UIS_cpuTemperature "Current temperature reported for cpu";
CM_ SG_ 1056 UIS_clusterMemUsage "cluster's Resident Memory usage in MB";
CM_ SG_ 1056 UIS_clusterDisplayState "Reports the instrument cluster display state.";
CM_ SG_ 1056 UIS_clusterCPUUsage "cluster's CPU usage in CPU usage %";
CM_ SG_ 1056 UIS_chargeOnSolarNoChargeReason "Reason car is not charging on solar";
CM_ SG_ 1056 UIS_chargeLocationId "Privacy-respecting region identifier for charge location (1.1km accuracy, requires user consent via Software > Controls > Data Sharing)";
CM_ SG_ 1056 UIS_centerDisplayState "Reports the center display state.";
CM_ SG_ 1056 UIS_centerDisplayEvent "Reports the events that cause center display state transitions.";
CM_ SG_ 1056 UIS_cellularLinkManagerState "CellLink Manager state";
CM_ SG_ 1056 UIS_cellularConnectivityStatus "Reports the abstracted status of overall connectivity on the infotainment.";
CM_ SG_ 1056 UIS_carAssistState "Car Assist State";
CM_ SG_ 1056 UIS_carAssistSessionCount "Car Assist Session Count";
CM_ SG_ 1056 UIS_carAssistMicMuted "Reports whether the car assist microphone is muted or unmuted.";
CM_ SG_ 1056 UIS_carAssistMicAlsaRms "Monitors the car assist microphone Advanced Linux Sound Architecture (ALSA) Root Mean Squared (RMS).";
CM_ SG_ 1056 UIS_carAssistErrorCode "Car Assist Error Code";
CM_ SG_ 1056 UIS_cameraSelectableRenderState "Indicates if the touchscreen UI software has composited at least one new selectable stream camera window frame.";
CM_ SG_ 1056 UIS_cameraSelectablePipeline "Reports the selectable stream camera pipeline state.";
CM_ SG_ 1056 UIS_cameraSelectablePacketState "Indicates if Infotainment detects selectable stream camera UDP packets from Autopilot.";
CM_ SG_ 1056 UIS_cameraRearViewRenderState "Indicates if the touchscreen UI software has composited at least one new rear view camera window frame.";
CM_ SG_ 1056 UIS_cameraRearViewPacketState "Indicates if Infotainment detects rear view camera UDP packets from Autopilot.";
CM_ SG_ 1056 UIS_cameraRRepeaterStreamMissing "Signal representing if left repeater camera stream is active within videod";
CM_ SG_ 1056 UIS_cameraRRepeaterRenderState "Indicates if the touchscreen UI software has composited at least one new right repeater camera window frame.";
CM_ SG_ 1056 UIS_cameraRRepeaterPopup "Right repeater camera popup state";
CM_ SG_ 1056 UIS_cameraRRepeaterPipeline "Right repeater videod pipeline state";
CM_ SG_ 1056 UIS_cameraRRepeaterPacketState "Indicates if Infotainment detects right repeater camera UDP packets from Autopilot.";
CM_ SG_ 1056 UIS_cameraRDownwardRenderState "Indicates if the touchscreen UI software has composited at least one new right downward camera window frame.";
CM_ SG_ 1056 UIS_cameraRDownwardPacketState "Indicates if Infotainment detects right downward camera UDP packets from Autopilot.";
CM_ SG_ 1056 UIS_cameraLRepeaterStreamMissing "Signal representing if left repeater camera stream is active within videod";
CM_ SG_ 1056 UIS_cameraLRepeaterRenderState "Indicates if the touchscreen UI software has composited at least one new left repeater camera window frame.";
CM_ SG_ 1056 UIS_cameraLRepeaterPopup "Left repeater camera popup state";
CM_ SG_ 1056 UIS_cameraLRepeaterPipeline "Left repeater videod pipeline state";
CM_ SG_ 1056 UIS_cameraLRepeaterPacketState "Indicates if Infotainment detects left repeater camera UDP packets from Autopilot.";
CM_ SG_ 1056 UIS_cameraLDownwardRenderState "Indicates if the touchscreen UI software has composited at least one new left downward camera window frame.";
CM_ SG_ 1056 UIS_cameraLDownwardPacketState "Indicates if Infotainment detects left downward camera UDP packets from Autopilot.";
CM_ SG_ 1056 UIS_cameraFrontRenderState "Indicates if the touchscreen UI software has composited at least one new front fascia camera window frame.";
CM_ SG_ 1056 UIS_cameraFrontPacketState "Indicates if Infotainment detects front fascia camera UDP packets from Autopilot.";
CM_ SG_ 1056 UIS_cameraBackupStreamMissing "Signal representing if backup camera stream is active within videod";
CM_ SG_ 1056 UIS_cameraBackupRenderState "Indicates if the touchscreen UI software has composited at least one new backup camera window frame.";
CM_ SG_ 1056 UIS_cameraBackupPopup "Reports the backup camera popup state.";
CM_ SG_ 1056 UIS_cameraBackupPipeline "Reports the backup camera video pipeline state.";
CM_ SG_ 1056 UIS_cameraBackupPacketState "Indicates if Infotainment detects backup camera UDP packets from Autopilot.";
CM_ SG_ 1056 UIS_cameraBackupFramerate "Reports the backup camera framerate.";
CM_ SG_ 1056 UIS_boardTemperature "Current temperature reported for board";
CM_ SG_ 1056 UIS_bluetoothState "Reports bluetooth state.";
CM_ SG_ 1056 UIS_bluetoothStackState "Bluetooth stack state";
CM_ SG_ 1056 UIS_bluetoothStackRearState "Bluetooth rear stack state";
CM_ SG_ 1056 UIS_bluetoothPairResult "Bluetooth pairing result";
CM_ SG_ 1056 UIS_bluetoothMemUsage "Reports the Bluetooth process resident memory usage in megabytes.";
CM_ SG_ 1056 UIS_bluetoothConnectionState "Reports the Bluetooth connection state.";
CM_ SG_ 1056 UIS_bluetoothCPUUsage "Reports the Bluetooth process Central Processing Unit (CPU) usage percentage.";
CM_ SG_ 1056 UIS_bluetoothAutoconnectAttempts "Reports the number of Bluetooth auto-connect attempts for the most recent connection cycle.";
CM_ SG_ 1056 UIS_bluetoothAutoconnectActive "Indicates that Bluetooth auto-connect is active.";
CM_ SG_ 1056 UIS_bluetoothAutoConnectionState "Reports the Bluetooth auto-connection state.";
CM_ SG_ 1056 UIS_backlightUserRequest "Reports the Graphical User Interface (GUI) backlight user request value.";
CM_ SG_ 1056 UIS_audioVolumeLevel "User facing volume level";
CM_ SG_ 1056 UIS_audioType "Shows which audio amplifier type is currently configured";
CM_ SG_ 1056 UIS_audioState "Shows the state of the audio system";
CM_ SG_ 1056 UIS_audioSource "Shows which internal audio source is currently active";
CM_ SG_ 1056 UIS_audioPWSGain "Reports the pedestrian warning system volume in decibels.";
CM_ SG_ 1056 UIS_audioMediaPlaying "Shows which media source is currently being played";
CM_ SG_ 1056 UIS_audioMediaBrowsing "Shows which media source is currently being viewed";
CM_ SG_ 1056 UIS_audioA2BRediscoveryCount "Shows the count of a2b rediscoveries that have occurred";
CM_ SG_ 1056 UIS_apeHardwareMinorVersion "APE hardware minor version from device tree";
CM_ SG_ 1056 UIS_activeAppView "Shows the currently displayed app";
CM_ SG_ 1056 UIS_CamViewerServiceEnabled "Reports whether the cam-viewer service is enabled.";
CM_ BO_ 979 "Touchscreen user interface computer message: airbag cutoff status";
CM_ SG_ 979 UI_airbagCutoffSwState "Reports the front passenger airbag cutoff switch request.; raw 2 = signal not available (SNA)";
CM_ BO_ 1279 "Touchscreen user interface computer message: energy consumption info";
CM_ SG_ 1279 UI_energyConsumptionInfoIndex "Touchscreen user interface computer: energy consumption info index";
CM_ SG_ 1279 UI_energyLossTotal_epa "Energy amount for a given bucket for an energy consumption baseline (raw/real energy consumed)";
CM_ SG_ 1279 UI_energyLossDriving_epa "Energy amount for a given bucket for an energy consumption baseline (raw/real energy consumed)";
CM_ SG_ 1279 UI_energyLossClimate_epa "Energy amount for a given bucket for an energy consumption baseline (raw/real energy consumed)";
CM_ SG_ 1279 UI_energyLossBattCond_epa "Energy amount for a given bucket for an energy consumption baseline (raw/real energy consumed)";
CM_ SG_ 1279 UI_energyLossElevation_epa "Energy amount for a given bucket for an energy consumption baseline (raw/real energy consumed)";
CM_ SG_ 1279 UI_energyLossAcc_epa "Energy amount for a given bucket for an energy consumption baseline (raw/real energy consumed)";
CM_ SG_ 1279 UI_energyLossTotalSinceCharge_ep "Energy amount for a given bucket for an energy consumption baseline (raw/real energy consumed)";
CM_ SG_ 1279 UI_energyLossDrivingSinceCharge_ "Energy amount for a given bucket for an energy consumption baseline (raw/real energy consumed)";
CM_ SG_ 1279 UI_energyLossClimateSinceCharge_ "Energy amount for a given bucket for an energy consumption baseline (raw/real energy consumed)";
CM_ SG_ 1279 UI_energyLossBattCondSinceCharge "Energy amount for a given bucket for an energy consumption baseline (raw/real energy consumed)";
CM_ SG_ 1279 UI_energyLossElevationSinceCharg "Energy amount for a given bucket for an energy consumption baseline (raw/real energy consumed)";
CM_ SG_ 1279 UI_energyLossAccSinceCharge_epa "Energy amount for a given bucket for an energy consumption baseline (raw/real energy consumed)";
CM_ SG_ 1279 UI_energyLossTotalSinceTripStart "Energy amount for a given bucket for an energy consumption baseline (raw/real energy consumed)";
CM_ SG_ 1279 UI_energyLossDrivingSinceTripSta "Energy amount for a given bucket for an energy consumption baseline (raw/real energy consumed)";
CM_ SG_ 1279 UI_energyLossClimateSinceTripSta "Energy amount for a given bucket for an energy consumption baseline (raw/real energy consumed)";
CM_ SG_ 1279 UI_energyLossBattCondSinceTripSt "Energy amount for a given bucket for an energy consumption baseline (raw/real energy consumed)";
CM_ SG_ 1279 UI_energyLossElevationSinceTripS "Energy amount for a given bucket for an energy consumption baseline (raw/real energy consumed)";
CM_ SG_ 1279 UI_energyLossAccSinceTripStart "Energy amount for a given bucket for an energy consumption baseline (raw/real energy consumed)";
CM_ SG_ 1279 UI_energyDeltaTotal_epa "Energy amount for a given bucket for an energy consumption baseline (raw/real energy consumed)";
CM_ SG_ 1279 UI_energyDeltaDriving_epa "Energy amount for a given bucket for an energy consumption baseline (raw/real energy consumed)";
CM_ SG_ 1279 UI_energyDeltaClimate_epa "Energy amount for a given bucket for an energy consumption baseline (raw/real energy consumed)";
CM_ SG_ 1279 UI_energyDeltaBattCond_epa "Energy amount for a given bucket for an energy consumption baseline (raw/real energy consumed)";
CM_ SG_ 1279 UI_energyDeltaElevation_epa "Energy amount for a given bucket for an energy consumption baseline (raw/real energy consumed)";
CM_ SG_ 1279 UI_energyDeltaAcc_epa "Energy amount for a given bucket for an energy consumption baseline (raw/real energy consumed)";
CM_ SG_ 1279 UI_uiDeltaOffsetTotal_epa "Energy amount for a given bucket for an energy consumption baseline (raw/real energy consumed)";
CM_ SG_ 1279 UI_uiDeltaOffsetDriving_epa "Energy amount for a given bucket for an energy consumption baseline (raw/real energy consumed)";
CM_ SG_ 1279 UI_uiDeltaOffsetClimate_epa "Energy amount for a given bucket for an energy consumption baseline (raw/real energy consumed)";
CM_ SG_ 1279 UI_uiDeltaOffsetBattCond_epa "Energy amount for a given bucket for an energy consumption baseline (raw/real energy consumed)";
CM_ SG_ 1279 UI_uiDeltaOffsetElevation_epa "Energy amount for a given bucket for an energy consumption baseline (raw/real energy consumed)";
CM_ SG_ 1279 UI_uiDeltaOffsetAcc_epa "Energy amount for a given bucket for an energy consumption baseline (raw/real energy consumed)";
CM_ SG_ 1279 UI_rawToUiEnergyRatio_epa "Ratio used for conversion between UI and raw energy domains";
CM_ SG_ 1279 UI_driveDistance_epa "Distance driven for an energy consumption baseline";
CM_ SG_ 1279 UI_energyDeltaTotalSinceCharge_e "Energy amount for a given bucket for an energy consumption baseline (raw/real energy consumed)";
CM_ SG_ 1279 UI_energyDeltaDrivingSinceCharge "Energy amount for a given bucket for an energy consumption baseline (raw/real energy consumed)";
CM_ SG_ 1279 UI_energyDeltaClimateSinceCharge "Energy amount for a given bucket for an energy consumption baseline (raw/real energy consumed)";
CM_ SG_ 1279 UI_energyDeltaBattCondSinceCharg "Energy amount for a given bucket for an energy consumption baseline (raw/real energy consumed)";
CM_ SG_ 1279 UI_energyDeltaElevationSinceChar "Energy amount for a given bucket for an energy consumption baseline (raw/real energy consumed)";
CM_ SG_ 1279 UI_energyDeltaAccSinceCharge_epa "Energy amount for a given bucket for an energy consumption baseline (raw/real energy consumed)";
CM_ SG_ 1279 UI_uiDeltaOffsetTotalSinceCharge "Energy amount for a given bucket for an energy consumption baseline (raw/real energy consumed)";
CM_ SG_ 1279 UI_uiDeltaOffsetDrivingSinceChar "Energy amount for a given bucket for an energy consumption baseline (raw/real energy consumed)";
CM_ SG_ 1279 UI_uiDeltaOffsetClimateSinceChar "Energy amount for a given bucket for an energy consumption baseline (raw/real energy consumed)";
CM_ SG_ 1279 UI_uiDeltaOffsetBattCondSinceCha "Energy amount for a given bucket for an energy consumption baseline (raw/real energy consumed)";
CM_ SG_ 1279 UI_uiDeltaOffsetElevationSinceCh "Energy amount for a given bucket for an energy consumption baseline (raw/real energy consumed)";
CM_ SG_ 1279 UI_uiDeltaOffsetAccSinceCharge_e "Energy amount for a given bucket for an energy consumption baseline (raw/real energy consumed)";
CM_ SG_ 1279 UI_rawToUiEnergyRatioSinceCharge "Ratio used for conversion between UI and raw energy domains";
CM_ SG_ 1279 UI_driveDistanceSinceCharge_epa "Distance driven for an energy consumption baseline";
CM_ SG_ 1279 UI_energyDeltaTotalSinceTripStar "Energy amount for a given bucket for an energy consumption baseline (raw/real energy consumed)";
CM_ SG_ 1279 UI_energyDeltaDrivingSinceTripSt "Energy amount for a given bucket for an energy consumption baseline (raw/real energy consumed)";
CM_ SG_ 1279 UI_energyDeltaClimateSinceTripSt "Energy amount for a given bucket for an energy consumption baseline (raw/real energy consumed)";
CM_ SG_ 1279 UI_energyDeltaBattCondSinceTripS "Energy amount for a given bucket for an energy consumption baseline (raw/real energy consumed)";
CM_ SG_ 1279 UI_energyDeltaElevationSinceTrip "Energy amount for a given bucket for an energy consumption baseline (raw/real energy consumed)";
CM_ SG_ 1279 UI_energyDeltaAccSinceTripStart "Energy amount for a given bucket for an energy consumption baseline (raw/real energy consumed)";
CM_ SG_ 1279 UI_uiDeltaOffsetTotalSinceTripSt "Energy amount for a given bucket for an energy consumption baseline (raw/real energy consumed)";
CM_ SG_ 1279 UI_uiDeltaOffsetDrivingSinceTrip "Energy amount for a given bucket for an energy consumption baseline (raw/real energy consumed)";
CM_ SG_ 1279 UI_uiDeltaOffsetClimateSinceTrip "Energy amount for a given bucket for an energy consumption baseline (raw/real energy consumed)";
CM_ SG_ 1279 UI_uiDeltaOffsetBattCondSinceTri "Energy amount for a given bucket for an energy consumption baseline (raw/real energy consumed)";
CM_ SG_ 1279 UI_uiDeltaOffsetElevationSinceTr "Energy amount for a given bucket for an energy consumption baseline (raw/real energy consumed)";
CM_ SG_ 1279 UI_uiDeltaOffsetAccSinceTripStar "Energy amount for a given bucket for an energy consumption baseline (raw/real energy consumed)";
CM_ SG_ 1279 UI_rawToUiEnergyRatioSinceTripSt "Ratio used for conversion between UI and raw energy domains";
CM_ SG_ 1279 UI_driveDistanceSinceTripStart "Distance driven for an energy consumption baseline";
CM_ SG_ 1279 UI_trailerMass "Trailer mass from user input";
CM_ BO_ 666 "Touchscreen user interface computer message: seat control";
CM_ SG_ 666 UI_seatControlIndex "Touchscreen user interface computer: seat control index";
CM_ SG_ 666 UI_3RSeatChildLock "Reports the state of 3rd row seat fold flat child lock from the UI";
CM_ SG_ 666 UI_left3RowSeatAdjustmentRequest "Reports request from the touchscreen User Interface (UI) to actuate the left third row seat.";
CM_ SG_ 666 UI_right3RowSeatAdjustmentReques "Reports request from the touchscreen User Interface (UI) to actuate the right third row seat.";
CM_ SG_ 666 UI_2RLeftSeatFanReq "Request for second row left seat ventilation";
CM_ SG_ 666 UI_2RRightSeatFanReq "Request for second row right seat ventilation";
CM_ SG_ 666 UI_seatChoreographyStopRequest "Reports if the UI requests to stop the seat choreography";
CM_ BO_ 563 "Touchscreen user interface computer message: stalkless control";
CM_ SG_ 563 UI_gearRequest "UI gear request from UI; raw 0 = signal not available (SNA)";
CM_ SG_ 563 UI_gearStripShowing "UI communicating to GTW that the gear strip is visible on the screen as part of a handshake";
CM_ SG_ 563 UI_gearStripForceShow "UI request to GTW to show the gear strip";
CM_ SG_ 563 UI_autoParkAvailable "UI communicating to GTW that the autpark functionality is available";
CM_ SG_ 563 UI_gearStripSuppressActive "UI communicating to GTW that the gear strip should not be shown";
CM_ SG_ 563 UI_gearNeutralPressed "Neutral button is being pressed";
CM_ BO_ 986 "Touchscreen user interface computer message: status3";
CM_ SG_ 986 UI_wifiRegDomain "Indicates the Wi-Fi regulatory domain.";
CM_ SG_ 986 UI_wifiTethered "Monitors whether Wi-Fi is connected while driving.";
CM_ BO_ 661 "Touchscreen user interface computer message: system monitor";
CM_ SG_ 661 UI_systemMonitorIndex "Touchscreen user interface computer: system monitor index";
CM_ SG_ 661 UI_SystemMemUsage "Monitors system memory usage";
CM_ SG_ 661 UI_QtCarMemUsage "Monitors memory usage of the primary User Interface application";
CM_ SG_ 661 UI_QtCarCPUUsage "Monitors CPU usage of the primary User Interface application";
CM_ SG_ 661 UI_SystemCPUUsage "Monitors system CPU usage";
CM_ BO_ 1263 "Touchscreen user interface computer message: trip planner info";
CM_ SG_ 1263 UI_fwHeatOnNavArrivalSOE "Energy percentages shown in the UI";
CM_ SG_ 1263 UI_voyagerHeatOnNavArrivalSOE "Energy percentages shown in the UI";
CM_ BO_ 139 "Touchscreen user interface computer message: trip planning2";
CM_ SG_ 139 UI_maxSpeedToReachDestination "maximum speed to reach destination without significant risk of running out of energy; raw 65535 = signal not available (SNA)";
CM_ SG_ 139 UI_timeToDestination "remaining time to reach destination; raw 65535 = signal not available (SNA)";
CM_ BO_ 1173 "Touchscreen user interface computer message: trip planning3";
CM_ SG_ 1173 UI_predictedEnergy "initially predicted energy in kWh for current location along navigation route; raw 32768 = signal not available (SNA)";
CM_ SG_ 1173 UI_hindsightEnergy "hindsight energy, the model predicted energy based on measured speed and acceleration for the current location along navigation route; raw 32768 = signal not available (SNA)";
CM_ BO_ 764 "VCSEAT2L ECU message: seat status";
CM_ SG_ 764 VCSEAT2L_row2SeatStatusIndex "VCSEAT2L ECU: row2 seat status index";
CM_ SG_ 764 VCSEAT2L_seatTrackPosReal "Reports real position of seat track";
CM_ SG_ 764 VCSEAT2L_seatTrackPosOffset "VCSEAT2L ECU: seat track pos offset";
CM_ SG_ 764 VCSEAT2L_seatReclineState "Reports the active state of the 2nd row seat recliner; raw 15 = signal not available (SNA)";
CM_ SG_ 764 VCSEAT2L_seatReclineCalibrated "Reports calibration status of the 2nd row seat recliner";
CM_ SG_ 764 VCSEAT2L_seatReclinePositionStat "Reports the active position state of the 2nd row seat recliner; raw 4 = signal not available (SNA)";
CM_ SG_ 764 VCSEAT2L_seatReclineAbsPosS_0001 "VCSEAT2L ECU: seat recline abs pos switch trans point";
CM_ SG_ 764 VCSEAT2L_seatReclineAbsPosSwitch "Reports the status of 2nd row seat recline absolute position (comfort zone) switch; raw 0 = signal not available (SNA)";
CM_ SG_ 764 VCSEAT2L_seatReclineFoldAllowed "VCSEAT2L ECU: seat recline fold allowed";
CM_ SG_ 764 VCSEAT2L_seatReclineUnfoldAllowe "VCSEAT2L ECU: seat recline unfold allowed";
CM_ SG_ 764 VCSEAT2L_seatReclineAdjustmentAl "VCSEAT2L ECU: seat recline adjustment allowed";
CM_ SG_ 764 VCSEAT2L_seat1RClashAvoidanceBlo "VCSEAT2L ECU: seat1 r clash avoidance blocked reason";
CM_ SG_ 764 VCSEAT2L_seat1RClashAvoidanceSta "VCSEAT2L ECU: seat1 r clash avoidance state";
CM_ SG_ 764 VCSEAT2L_seatReclineChoreoBlocke "VCSEAT2L ECU: seat recline choreo blocked by occupancy";
CM_ SG_ 764 VCSEAT2L_seatReclineNextToggleDi "VCSEAT2L ECU: seat recline next toggle direction; raw 2 = signal not available (SNA)";
CM_ BO_ 1986 "VCSEAT2L ECU message: seat status2";
CM_ SG_ 1986 VCSEAT2L_seatStatus2Index "VCSEAT2L ECU: seat status2 index";
CM_ SG_ 1986 VCSEAT2L_choreography2RState "VCSEAT2L ECU: choreography2 r state";
CM_ SG_ 1986 VCSEAT2L_choreography3RState "VCSEAT2L ECU: choreography3 r state";
CM_ SG_ 1986 VCSEAT2L_choreography1RIsAllowed "VCSEAT2L ECU: choreography1 r is allowed to move";
CM_ SG_ 1986 VCSEAT2L_choreography2RIsAllowed "VCSEAT2L ECU: choreography2 r is allowed to move";
CM_ SG_ 1986 VCSEAT2L_choreography1RTrackVelo "VCSEAT2L ECU: choreography1 r track velocity type";
CM_ SG_ 1986 VCSEAT2L_choreography1RBackrestV "VCSEAT2L ECU: choreography1 r backrest velocity type";
CM_ SG_ 1986 VCSEAT2L_choreography2RTrackVelo "VCSEAT2L ECU: choreography2 r track velocity type";
CM_ SG_ 1986 VCSEAT2L_choreography2RBackrestV "VCSEAT2L ECU: choreography2 r backrest velocity type";
CM_ SG_ 1986 VCSEAT2L_choreography3RBackrestV "VCSEAT2L ECU: choreography3 r backrest velocity type";
CM_ SG_ 1986 VCSEAT2L_choreographyState "VCSEAT2L ECU: choreography state";
CM_ SG_ 1986 VCSEAT2L_choreographyCollisionPa "VCSEAT2L ECU: choreography collision pair";
CM_ SG_ 1986 VCSEAT2L_2rMovingForChoreography "VCSEAT2L ECU: 2r moving for choreography";
CM_ BO_ 746 "VCSEAT2R ECU message: seat status2";
CM_ SG_ 746 VCSEAT2R_seatStatus2Index "VCSEAT2R ECU: seat status2 index";
CM_ SG_ 746 VCSEAT2R_choreography2RState "VCSEAT2R ECU: choreography2 r state";
CM_ SG_ 746 VCSEAT2R_choreography3RState "VCSEAT2R ECU: choreography3 r state";
CM_ SG_ 746 VCSEAT2R_choreography1RIsAllowed "VCSEAT2R ECU: choreography1 r is allowed to move";
CM_ SG_ 746 VCSEAT2R_choreography2RIsAllowed "VCSEAT2R ECU: choreography2 r is allowed to move";
CM_ SG_ 746 VCSEAT2R_choreography1RTrackVelo "VCSEAT2R ECU: choreography1 r track velocity type";
CM_ SG_ 746 VCSEAT2R_choreography1RBackrestV "VCSEAT2R ECU: choreography1 r backrest velocity type";
CM_ SG_ 746 VCSEAT2R_choreography2RTrackVelo "VCSEAT2R ECU: choreography2 r track velocity type";
CM_ SG_ 746 VCSEAT2R_choreography2RBackrestV "VCSEAT2R ECU: choreography2 r backrest velocity type";
CM_ SG_ 746 VCSEAT2R_choreography3RBackrestV "VCSEAT2R ECU: choreography3 r backrest velocity type";
CM_ SG_ 746 VCSEAT2R_choreographyState "VCSEAT2R ECU: choreography state";
CM_ SG_ 746 VCSEAT2R_choreographyCollisionPa "VCSEAT2R ECU: choreography collision pair";
CM_ SG_ 746 VCSEAT2R_2rMovingForChoreography "VCSEAT2R ECU: 2r moving for choreography";
BA_DEF_ BO_ "GenMsgCycleTime" INT 0 3600000;
BA_DEF_ BO_ "GenMsgSendType" ENUM "Cyclic","NotUsed","NotUsed","NotUsed","NotUsed","NotUsed","NotUsed","IfActive","NoMsgSendType","NotUsed";
BA_DEF_ BO_ "VFrameFormat" ENUM "StandardCAN","ExtendedCAN","reserved","J1939PG","reserved","reserved","reserved","reserved","reserved","reserved","reserved","reserved","reserved","reserved","StandardCAN_FD","ExtendedCAN_FD";
BA_DEF_ BO_ "CANFD_BRS" ENUM "0","1";
BA_DEF_ SG_ "GenSigSNA" STRING;
BA_DEF_ SG_ "SystemSignalLongSymbol" STRING;
BA_DEF_ SG_ "Confidence" ENUM "validated","plausible","layout-only","contradicted";
BA_DEF_DEF_ "GenMsgCycleTime" 0;
BA_DEF_DEF_ "GenMsgSendType" "NoMsgSendType";
BA_DEF_DEF_ "VFrameFormat" "StandardCAN";
BA_DEF_DEF_ "CANFD_BRS" "1";
BA_DEF_DEF_ "GenSigSNA" "";
BA_DEF_DEF_ "SystemSignalLongSymbol" "";
BA_DEF_DEF_ "Confidence" "layout-only";
BA_ "GenMsgCycleTime" BO_ 979 500;
BA_ "GenMsgSendType" BO_ 979 0;
BA_ "GenMsgCycleTime" BO_ 1279 1000;
BA_ "GenMsgSendType" BO_ 1279 0;
BA_ "GenMsgCycleTime" BO_ 666 500;
BA_ "GenMsgSendType" BO_ 666 0;
BA_ "GenMsgCycleTime" BO_ 563 500;
BA_ "GenMsgSendType" BO_ 563 0;
BA_ "GenMsgCycleTime" BO_ 986 1000;
BA_ "GenMsgSendType" BO_ 986 0;
BA_ "GenMsgCycleTime" BO_ 661 15000;
BA_ "GenMsgSendType" BO_ 661 0;
BA_ "GenMsgCycleTime" BO_ 1263 1000;
BA_ "GenMsgSendType" BO_ 1263 0;
BA_ "GenMsgCycleTime" BO_ 139 1000;
BA_ "GenMsgSendType" BO_ 139 0;
BA_ "GenMsgCycleTime" BO_ 1173 1000;
BA_ "GenMsgSendType" BO_ 1173 0;
BA_ "GenMsgCycleTime" BO_ 764 100;
BA_ "GenMsgSendType" BO_ 764 0;
BA_ "GenMsgCycleTime" BO_ 1986 200;
BA_ "GenMsgSendType" BO_ 1986 0;
BA_ "GenMsgCycleTime" BO_ 746 200;
BA_ "GenMsgSendType" BO_ 746 0;
BA_ "Confidence" SG_ 1056 UIS_logMux 1;
BA_ "Confidence" SG_ 1056 UIS_wifiTemperature 0;
BA_ "Confidence" SG_ 1056 UIS_wifiStackState 0;
BA_ "Confidence" SG_ 1056 UIS_wifiBars 0;
BA_ "Confidence" SG_ 1056 UIS_wifiAutoJoinLowRSSI 0;
BA_ "Confidence" SG_ 1056 UIS_valetMode 0;
BA_ "Confidence" SG_ 1056 UIS_uiQtCarUptime 0;
BA_ "Confidence" SG_ 1056 UIS_uiMeanFPS 0;
BA_ "Confidence" SG_ 1056 UIS_tunerVoltageOperation 0;
BA_ "Confidence" SG_ 1056 UIS_tunerVoltageAntenna2 0;
BA_ "Confidence" SG_ 1056 UIS_tunerVoltageAntenna1 0;
BA_ "Confidence" SG_ 1056 UIS_tunerCurrentAntenna2 0;
BA_ "Confidence" SG_ 1056 UIS_tunerCurrentAntenna1 0;
BA_ "Confidence" SG_ 1056 UIS_tegraModemManState 0;
BA_ "Confidence" SG_ 1056 UIS_systemWakeTime 0;
BA_ "Confidence" SG_ 1056 UIS_systemUptime 0;
BA_ "Confidence" SG_ 1056 UIS_suspensionGeofence 0;
BA_ "Confidence" SG_ 1056 UIS_superchargePaymentNeeded 0;
BA_ "Confidence" SG_ 1056 UIS_sleepType 0;
BA_ "Confidence" SG_ 1056 UIS_sleepTime 0;
BA_ "Confidence" SG_ 1056 UIS_sleepState 0;
BA_ "Confidence" SG_ 1056 UIS_slackerLoginResult 0;
BA_ "Confidence" SG_ 1056 UIS_sentryState 0;
BA_ "Confidence" SG_ 1056 UIS_sentryNeedsNap 0;
BA_ "Confidence" SG_ 1056 UIS_sentryIncidentCount 0;
BA_ "Confidence" SG_ 1056 UIS_scheduledChargingMode 0;
BA_ "Confidence" SG_ 1056 UIS_scheduleChargeStartTime 0;
BA_ "Confidence" SG_ 1056 UIS_scheduleChargeEndTime 0;
BA_ "Confidence" SG_ 1056 UIS_remoteRequestType 0;
BA_ "Confidence" SG_ 1056 UIS_rearDisplayUserPresent 0;
BA_ "Confidence" SG_ 1056 UIS_rearDisplayState 0;
BA_ "Confidence" SG_ 1056 UIS_powerManagerState 0;
BA_ "GenSigSNA" SG_ 1056 UIS_powerManagerState "18";
BA_ "Confidence" SG_ 1056 UIS_polytopiax8664MemUsage 0;
BA_ "Confidence" SG_ 1056 UIS_polytopiax8664CPUUsage 0;
BA_ "Confidence" SG_ 1056 UIS_navServiceError 0;
BA_ "Confidence" SG_ 1056 UIS_navAudioVolume 0;
BA_ "Confidence" SG_ 1056 UIS_muteNavVolume 0;
BA_ "Confidence" SG_ 1056 UIS_modemECallppAvail 0;
BA_ "Confidence" SG_ 1056 UIS_modemBusyActive 0;
BA_ "Confidence" SG_ 1056 UIS_mirrorGeofenceActive 0;
BA_ "Confidence" SG_ 1056 UIS_mediaPlaybackStatus 0;
BA_ "Confidence" SG_ 1056 UIS_mediaNeedAuthToken 0;
BA_ "Confidence" SG_ 1056 UIS_inSuperchargerGeofence 0;
BA_ "Confidence" SG_ 1056 UIS_homelinkState 0;
BA_ "Confidence" SG_ 1056 UIS_headsetPairResult 0;
BA_ "Confidence" SG_ 1056 UIS_headsetConnectionState 0;
BA_ "Confidence" SG_ 1056 UIS_gpsmanagerMemUsage 0;
BA_ "Confidence" SG_ 1056 UIS_gpsmanagerCPUUsage 0;
BA_ "Confidence" SG_ 1056 UIS_featureSuperchargingEnabled 0;
BA_ "Confidence" SG_ 1056 UIS_dmRearTouchDeviceExists 0;
BA_ "Confidence" SG_ 1056 UIS_dmRearPowerState 0;
BA_ "Confidence" SG_ 1056 UIS_dmRearLinkCheckOk 0;
BA_ "Confidence" SG_ 1056 UIS_dmRearEnabled 0;
BA_ "Confidence" SG_ 1056 UIS_dmRearConnected 0;
BA_ "Confidence" SG_ 1056 UIS_dmRearBacklightDutyCycle 0;
BA_ "Confidence" SG_ 1056 UIS_dmRearBacklightDevExists 0;
BA_ "Confidence" SG_ 1056 UIS_dmIcuPowerState 0;
BA_ "Confidence" SG_ 1056 UIS_dmIcuLinkCheckOk 0;
BA_ "Confidence" SG_ 1056 UIS_dmIcuEnabled 0;
BA_ "Confidence" SG_ 1056 UIS_dmIcuConnected 0;
BA_ "Confidence" SG_ 1056 UIS_dmIcuBacklightDutyCycle 0;
BA_ "Confidence" SG_ 1056 UIS_dmIcuBacklightDevExists 0;
BA_ "Confidence" SG_ 1056 UIS_dmGatewayLinkWedged 0;
BA_ "Confidence" SG_ 1056 UIS_dmCenterTouchDeviceExists 0;
BA_ "Confidence" SG_ 1056 UIS_dmCenterPowerState 0;
BA_ "Confidence" SG_ 1056 UIS_dmCenterOsdDisplayedState 0;
BA_ "Confidence" SG_ 1056 UIS_dmCenterLinkCheckOk 0;
BA_ "Confidence" SG_ 1056 UIS_dmCenterEnabled 0;
BA_ "Confidence" SG_ 1056 UIS_dmCenterConnected 0;
BA_ "Confidence" SG_ 1056 UIS_dmCenterBacklightPowerLevel 0;
BA_ "Confidence" SG_ 1056 UIS_dmCenterBacklightDutyCycle 0;
BA_ "Confidence" SG_ 1056 UIS_dmCenterBacklightDevExists 0;
BA_ "Confidence" SG_ 1056 UIS_dmCenterBacklightControlDefe 0;
BA_ "SystemSignalLongSymbol" SG_ 1056 UIS_dmCenterBacklightControlDefe "UIS_dmCenterBacklightControlDeferred";
BA_ "Confidence" SG_ 1056 UIS_dgpuTemperature 0;
BA_ "Confidence" SG_ 1056 UIS_dashcamviewerMemUsage 0;
BA_ "Confidence" SG_ 1056 UIS_dashcamviewerCPUUsage 0;
BA_ "Confidence" SG_ 1056 UIS_dashcamStorageState 0;
BA_ "Confidence" SG_ 1056 UIS_dashcamStorageSentryMB 0;
BA_ "Confidence" SG_ 1056 UIS_dashcamStorageSavedMB 0;
BA_ "Confidence" SG_ 1056 UIS_dashcamStorageRecentMB 0;
BA_ "Confidence" SG_ 1056 UIS_dashcamStorageAvailableMB 0;
BA_ "Confidence" SG_ 1056 UIS_dashcamState 0;
BA_ "Confidence" SG_ 1056 UIS_cpuTemperature 0;
BA_ "Confidence" SG_ 1056 UIS_clusterMemUsage 0;
BA_ "Confidence" SG_ 1056 UIS_clusterDisplayState 0;
BA_ "Confidence" SG_ 1056 UIS_clusterCPUUsage 0;
BA_ "Confidence" SG_ 1056 UIS_chargeOnSolarNoChargeReason 0;
BA_ "Confidence" SG_ 1056 UIS_chargeLocationId 0;
BA_ "Confidence" SG_ 1056 UIS_centerDisplayState 0;
BA_ "Confidence" SG_ 1056 UIS_centerDisplayEvent 0;
BA_ "Confidence" SG_ 1056 UIS_cellularLinkManagerState 0;
BA_ "Confidence" SG_ 1056 UIS_cellularConnectivityStatus 0;
BA_ "Confidence" SG_ 1056 UIS_carAssistState 0;
BA_ "Confidence" SG_ 1056 UIS_carAssistSessionCount 0;
BA_ "Confidence" SG_ 1056 UIS_carAssistMicMuted 0;
BA_ "Confidence" SG_ 1056 UIS_carAssistMicAlsaRms 0;
BA_ "Confidence" SG_ 1056 UIS_carAssistErrorCode 0;
BA_ "Confidence" SG_ 1056 UIS_cameraSelectableRenderState 0;
BA_ "Confidence" SG_ 1056 UIS_cameraSelectablePipeline 0;
BA_ "Confidence" SG_ 1056 UIS_cameraSelectablePacketState 0;
BA_ "Confidence" SG_ 1056 UIS_cameraRearViewRenderState 0;
BA_ "Confidence" SG_ 1056 UIS_cameraRearViewPacketState 0;
BA_ "Confidence" SG_ 1056 UIS_cameraRRepeaterStreamMissing 0;
BA_ "Confidence" SG_ 1056 UIS_cameraRRepeaterRenderState 0;
BA_ "Confidence" SG_ 1056 UIS_cameraRRepeaterPopup 0;
BA_ "Confidence" SG_ 1056 UIS_cameraRRepeaterPipeline 0;
BA_ "Confidence" SG_ 1056 UIS_cameraRRepeaterPacketState 0;
BA_ "Confidence" SG_ 1056 UIS_cameraRDownwardRenderState 0;
BA_ "Confidence" SG_ 1056 UIS_cameraRDownwardPacketState 0;
BA_ "Confidence" SG_ 1056 UIS_cameraLRepeaterStreamMissing 0;
BA_ "Confidence" SG_ 1056 UIS_cameraLRepeaterRenderState 0;
BA_ "Confidence" SG_ 1056 UIS_cameraLRepeaterPopup 0;
BA_ "Confidence" SG_ 1056 UIS_cameraLRepeaterPipeline 0;
BA_ "Confidence" SG_ 1056 UIS_cameraLRepeaterPacketState 0;
BA_ "Confidence" SG_ 1056 UIS_cameraLDownwardRenderState 0;
BA_ "Confidence" SG_ 1056 UIS_cameraLDownwardPacketState 0;
BA_ "Confidence" SG_ 1056 UIS_cameraFrontRenderState 0;
BA_ "Confidence" SG_ 1056 UIS_cameraFrontPacketState 0;
BA_ "Confidence" SG_ 1056 UIS_cameraBackupStreamMissing 0;
BA_ "Confidence" SG_ 1056 UIS_cameraBackupRenderState 0;
BA_ "Confidence" SG_ 1056 UIS_cameraBackupPopup 0;
BA_ "Confidence" SG_ 1056 UIS_cameraBackupPipeline 0;
BA_ "Confidence" SG_ 1056 UIS_cameraBackupPacketState 0;
BA_ "Confidence" SG_ 1056 UIS_cameraBackupFramerate 0;
BA_ "Confidence" SG_ 1056 UIS_boardTemperature 0;
BA_ "Confidence" SG_ 1056 UIS_bluetoothState 0;
BA_ "Confidence" SG_ 1056 UIS_bluetoothStackState 0;
BA_ "Confidence" SG_ 1056 UIS_bluetoothStackRearState 0;
BA_ "Confidence" SG_ 1056 UIS_bluetoothPairResult 0;
BA_ "Confidence" SG_ 1056 UIS_bluetoothMemUsage 0;
BA_ "Confidence" SG_ 1056 UIS_bluetoothConnectionState 0;
BA_ "Confidence" SG_ 1056 UIS_bluetoothCPUUsage 0;
BA_ "Confidence" SG_ 1056 UIS_bluetoothAutoconnectAttempts 0;
BA_ "Confidence" SG_ 1056 UIS_bluetoothAutoconnectActive 0;
BA_ "Confidence" SG_ 1056 UIS_bluetoothAutoConnectionState 0;
BA_ "Confidence" SG_ 1056 UIS_backlightUserRequest 0;
BA_ "Confidence" SG_ 1056 UIS_audioVolumeLevel 0;
BA_ "Confidence" SG_ 1056 UIS_audioType 0;
BA_ "Confidence" SG_ 1056 UIS_audioState 0;
BA_ "Confidence" SG_ 1056 UIS_audioSource 0;
BA_ "Confidence" SG_ 1056 UIS_audioPWSGain 0;
BA_ "Confidence" SG_ 1056 UIS_audioMediaPlaying 0;
BA_ "Confidence" SG_ 1056 UIS_audioMediaBrowsing 0;
BA_ "Confidence" SG_ 1056 UIS_audioA2BRediscoveryCount 0;
BA_ "Confidence" SG_ 1056 UIS_apeHardwareMinorVersion 0;
BA_ "Confidence" SG_ 1056 UIS_activeAppView 0;
BA_ "Confidence" SG_ 1056 UIS_CamViewerServiceEnabled 0;
BA_ "Confidence" SG_ 979 UI_airbagCutoffSwState 0;
BA_ "GenSigSNA" SG_ 979 UI_airbagCutoffSwState "2";
BA_ "Confidence" SG_ 1279 UI_energyConsumptionInfoIndex 1;
BA_ "Confidence" SG_ 1279 UI_energyLossTotal_epa 0;
BA_ "Confidence" SG_ 1279 UI_energyLossDriving_epa 0;
BA_ "Confidence" SG_ 1279 UI_energyLossClimate_epa 0;
BA_ "Confidence" SG_ 1279 UI_energyLossBattCond_epa 0;
BA_ "Confidence" SG_ 1279 UI_energyLossElevation_epa 0;
BA_ "Confidence" SG_ 1279 UI_energyLossAcc_epa 0;
BA_ "Confidence" SG_ 1279 UI_energyLossTotalSinceCharge_ep 0;
BA_ "SystemSignalLongSymbol" SG_ 1279 UI_energyLossTotalSinceCharge_ep "UI_energyLossTotalSinceCharge_epa";
BA_ "Confidence" SG_ 1279 UI_energyLossDrivingSinceCharge_ 0;
BA_ "SystemSignalLongSymbol" SG_ 1279 UI_energyLossDrivingSinceCharge_ "UI_energyLossDrivingSinceCharge_epa";
BA_ "Confidence" SG_ 1279 UI_energyLossClimateSinceCharge_ 0;
BA_ "SystemSignalLongSymbol" SG_ 1279 UI_energyLossClimateSinceCharge_ "UI_energyLossClimateSinceCharge_epa";
BA_ "Confidence" SG_ 1279 UI_energyLossBattCondSinceCharge 0;
BA_ "SystemSignalLongSymbol" SG_ 1279 UI_energyLossBattCondSinceCharge "UI_energyLossBattCondSinceCharge_epa";
BA_ "Confidence" SG_ 1279 UI_energyLossElevationSinceCharg 0;
BA_ "SystemSignalLongSymbol" SG_ 1279 UI_energyLossElevationSinceCharg "UI_energyLossElevationSinceCharge_epa";
BA_ "Confidence" SG_ 1279 UI_energyLossAccSinceCharge_epa 0;
BA_ "Confidence" SG_ 1279 UI_energyLossTotalSinceTripStart 0;
BA_ "Confidence" SG_ 1279 UI_energyLossDrivingSinceTripSta 0;
BA_ "SystemSignalLongSymbol" SG_ 1279 UI_energyLossDrivingSinceTripSta "UI_energyLossDrivingSinceTripStart";
BA_ "Confidence" SG_ 1279 UI_energyLossClimateSinceTripSta 0;
BA_ "SystemSignalLongSymbol" SG_ 1279 UI_energyLossClimateSinceTripSta "UI_energyLossClimateSinceTripStart";
BA_ "Confidence" SG_ 1279 UI_energyLossBattCondSinceTripSt 0;
BA_ "SystemSignalLongSymbol" SG_ 1279 UI_energyLossBattCondSinceTripSt "UI_energyLossBattCondSinceTripStart";
BA_ "Confidence" SG_ 1279 UI_energyLossElevationSinceTripS 0;
BA_ "SystemSignalLongSymbol" SG_ 1279 UI_energyLossElevationSinceTripS "UI_energyLossElevationSinceTripStart";
BA_ "Confidence" SG_ 1279 UI_energyLossAccSinceTripStart 0;
BA_ "Confidence" SG_ 1279 UI_energyDeltaTotal_epa 0;
BA_ "Confidence" SG_ 1279 UI_energyDeltaDriving_epa 0;
BA_ "Confidence" SG_ 1279 UI_energyDeltaClimate_epa 0;
BA_ "Confidence" SG_ 1279 UI_energyDeltaBattCond_epa 0;
BA_ "Confidence" SG_ 1279 UI_energyDeltaElevation_epa 0;
BA_ "Confidence" SG_ 1279 UI_energyDeltaAcc_epa 0;
BA_ "Confidence" SG_ 1279 UI_uiDeltaOffsetTotal_epa 0;
BA_ "Confidence" SG_ 1279 UI_uiDeltaOffsetDriving_epa 0;
BA_ "Confidence" SG_ 1279 UI_uiDeltaOffsetClimate_epa 0;
BA_ "Confidence" SG_ 1279 UI_uiDeltaOffsetBattCond_epa 0;
BA_ "Confidence" SG_ 1279 UI_uiDeltaOffsetElevation_epa 0;
BA_ "Confidence" SG_ 1279 UI_uiDeltaOffsetAcc_epa 0;
BA_ "Confidence" SG_ 1279 UI_rawToUiEnergyRatio_epa 0;
BA_ "Confidence" SG_ 1279 UI_driveDistance_epa 0;
BA_ "Confidence" SG_ 1279 UI_energyDeltaTotalSinceCharge_e 0;
BA_ "SystemSignalLongSymbol" SG_ 1279 UI_energyDeltaTotalSinceCharge_e "UI_energyDeltaTotalSinceCharge_epa";
BA_ "Confidence" SG_ 1279 UI_energyDeltaDrivingSinceCharge 0;
BA_ "SystemSignalLongSymbol" SG_ 1279 UI_energyDeltaDrivingSinceCharge "UI_energyDeltaDrivingSinceCharge_epa";
BA_ "Confidence" SG_ 1279 UI_energyDeltaClimateSinceCharge 0;
BA_ "SystemSignalLongSymbol" SG_ 1279 UI_energyDeltaClimateSinceCharge "UI_energyDeltaClimateSinceCharge_epa";
BA_ "Confidence" SG_ 1279 UI_energyDeltaBattCondSinceCharg 0;
BA_ "SystemSignalLongSymbol" SG_ 1279 UI_energyDeltaBattCondSinceCharg "UI_energyDeltaBattCondSinceCharge_epa";
BA_ "Confidence" SG_ 1279 UI_energyDeltaElevationSinceChar 0;
BA_ "SystemSignalLongSymbol" SG_ 1279 UI_energyDeltaElevationSinceChar "UI_energyDeltaElevationSinceCharge_epa";
BA_ "Confidence" SG_ 1279 UI_energyDeltaAccSinceCharge_epa 0;
BA_ "Confidence" SG_ 1279 UI_uiDeltaOffsetTotalSinceCharge 0;
BA_ "SystemSignalLongSymbol" SG_ 1279 UI_uiDeltaOffsetTotalSinceCharge "UI_uiDeltaOffsetTotalSinceCharge_epa";
BA_ "Confidence" SG_ 1279 UI_uiDeltaOffsetDrivingSinceChar 0;
BA_ "SystemSignalLongSymbol" SG_ 1279 UI_uiDeltaOffsetDrivingSinceChar "UI_uiDeltaOffsetDrivingSinceCharge_epa";
BA_ "Confidence" SG_ 1279 UI_uiDeltaOffsetClimateSinceChar 0;
BA_ "SystemSignalLongSymbol" SG_ 1279 UI_uiDeltaOffsetClimateSinceChar "UI_uiDeltaOffsetClimateSinceCharge_epa";
BA_ "Confidence" SG_ 1279 UI_uiDeltaOffsetBattCondSinceCha 0;
BA_ "SystemSignalLongSymbol" SG_ 1279 UI_uiDeltaOffsetBattCondSinceCha "UI_uiDeltaOffsetBattCondSinceCharge_epa";
BA_ "Confidence" SG_ 1279 UI_uiDeltaOffsetElevationSinceCh 0;
BA_ "SystemSignalLongSymbol" SG_ 1279 UI_uiDeltaOffsetElevationSinceCh "UI_uiDeltaOffsetElevationSinceCharge_epa";
BA_ "Confidence" SG_ 1279 UI_uiDeltaOffsetAccSinceCharge_e 0;
BA_ "SystemSignalLongSymbol" SG_ 1279 UI_uiDeltaOffsetAccSinceCharge_e "UI_uiDeltaOffsetAccSinceCharge_epa";
BA_ "Confidence" SG_ 1279 UI_rawToUiEnergyRatioSinceCharge 0;
BA_ "SystemSignalLongSymbol" SG_ 1279 UI_rawToUiEnergyRatioSinceCharge "UI_rawToUiEnergyRatioSinceCharge_epa";
BA_ "Confidence" SG_ 1279 UI_driveDistanceSinceCharge_epa 0;
BA_ "Confidence" SG_ 1279 UI_energyDeltaTotalSinceTripStar 0;
BA_ "SystemSignalLongSymbol" SG_ 1279 UI_energyDeltaTotalSinceTripStar "UI_energyDeltaTotalSinceTripStart";
BA_ "Confidence" SG_ 1279 UI_energyDeltaDrivingSinceTripSt 0;
BA_ "SystemSignalLongSymbol" SG_ 1279 UI_energyDeltaDrivingSinceTripSt "UI_energyDeltaDrivingSinceTripStart";
BA_ "Confidence" SG_ 1279 UI_energyDeltaClimateSinceTripSt 0;
BA_ "SystemSignalLongSymbol" SG_ 1279 UI_energyDeltaClimateSinceTripSt "UI_energyDeltaClimateSinceTripStart";
BA_ "Confidence" SG_ 1279 UI_energyDeltaBattCondSinceTripS 0;
BA_ "SystemSignalLongSymbol" SG_ 1279 UI_energyDeltaBattCondSinceTripS "UI_energyDeltaBattCondSinceTripStart";
BA_ "Confidence" SG_ 1279 UI_energyDeltaElevationSinceTrip 0;
BA_ "SystemSignalLongSymbol" SG_ 1279 UI_energyDeltaElevationSinceTrip "UI_energyDeltaElevationSinceTripStart";
BA_ "Confidence" SG_ 1279 UI_energyDeltaAccSinceTripStart 0;
BA_ "Confidence" SG_ 1279 UI_uiDeltaOffsetTotalSinceTripSt 0;
BA_ "SystemSignalLongSymbol" SG_ 1279 UI_uiDeltaOffsetTotalSinceTripSt "UI_uiDeltaOffsetTotalSinceTripStart";
BA_ "Confidence" SG_ 1279 UI_uiDeltaOffsetDrivingSinceTrip 0;
BA_ "SystemSignalLongSymbol" SG_ 1279 UI_uiDeltaOffsetDrivingSinceTrip "UI_uiDeltaOffsetDrivingSinceTripStart";
BA_ "Confidence" SG_ 1279 UI_uiDeltaOffsetClimateSinceTrip 0;
BA_ "SystemSignalLongSymbol" SG_ 1279 UI_uiDeltaOffsetClimateSinceTrip "UI_uiDeltaOffsetClimateSinceTripStart";
BA_ "Confidence" SG_ 1279 UI_uiDeltaOffsetBattCondSinceTri 0;
BA_ "SystemSignalLongSymbol" SG_ 1279 UI_uiDeltaOffsetBattCondSinceTri "UI_uiDeltaOffsetBattCondSinceTripStart";
BA_ "Confidence" SG_ 1279 UI_uiDeltaOffsetElevationSinceTr 0;
BA_ "SystemSignalLongSymbol" SG_ 1279 UI_uiDeltaOffsetElevationSinceTr "UI_uiDeltaOffsetElevationSinceTripStart";
BA_ "Confidence" SG_ 1279 UI_uiDeltaOffsetAccSinceTripStar 0;
BA_ "SystemSignalLongSymbol" SG_ 1279 UI_uiDeltaOffsetAccSinceTripStar "UI_uiDeltaOffsetAccSinceTripStart";
BA_ "Confidence" SG_ 1279 UI_rawToUiEnergyRatioSinceTripSt 0;
BA_ "SystemSignalLongSymbol" SG_ 1279 UI_rawToUiEnergyRatioSinceTripSt "UI_rawToUiEnergyRatioSinceTripStart";
BA_ "Confidence" SG_ 1279 UI_driveDistanceSinceTripStart 0;
BA_ "Confidence" SG_ 1279 UI_trailerMass 0;
BA_ "Confidence" SG_ 666 UI_seatControlIndex 1;
BA_ "Confidence" SG_ 666 UI_3RSeatChildLock 0;
BA_ "Confidence" SG_ 666 UI_left3RowSeatAdjustmentRequest 0;
BA_ "Confidence" SG_ 666 UI_right3RowSeatAdjustmentReques 0;
BA_ "SystemSignalLongSymbol" SG_ 666 UI_right3RowSeatAdjustmentReques "UI_right3RowSeatAdjustmentRequest";
BA_ "Confidence" SG_ 666 UI_2RLeftSeatFanReq 0;
BA_ "Confidence" SG_ 666 UI_2RRightSeatFanReq 0;
BA_ "Confidence" SG_ 666 UI_seatChoreographyStopRequest 0;
BA_ "Confidence" SG_ 563 UI_gearRequest 0;
BA_ "GenSigSNA" SG_ 563 UI_gearRequest "0";
BA_ "Confidence" SG_ 563 UI_gearStripShowing 0;
BA_ "Confidence" SG_ 563 UI_gearStripForceShow 0;
BA_ "Confidence" SG_ 563 UI_autoParkAvailable 0;
BA_ "Confidence" SG_ 563 UI_gearStripSuppressActive 0;
BA_ "Confidence" SG_ 563 UI_gearNeutralPressed 0;
BA_ "Confidence" SG_ 986 UI_wifiRegDomain 0;
BA_ "Confidence" SG_ 986 UI_wifiTethered 0;
BA_ "Confidence" SG_ 661 UI_systemMonitorIndex 1;
BA_ "Confidence" SG_ 661 UI_SystemMemUsage 0;
BA_ "Confidence" SG_ 661 UI_QtCarMemUsage 0;
BA_ "Confidence" SG_ 661 UI_QtCarCPUUsage 0;
BA_ "Confidence" SG_ 661 UI_SystemCPUUsage 0;
BA_ "Confidence" SG_ 1263 UI_fwHeatOnNavArrivalSOE 0;
BA_ "Confidence" SG_ 1263 UI_voyagerHeatOnNavArrivalSOE 0;
BA_ "Confidence" SG_ 139 UI_maxSpeedToReachDestination 0;
BA_ "GenSigSNA" SG_ 139 UI_maxSpeedToReachDestination "65535";
BA_ "Confidence" SG_ 139 UI_timeToDestination 0;
BA_ "GenSigSNA" SG_ 139 UI_timeToDestination "65535";
BA_ "Confidence" SG_ 1173 UI_predictedEnergy 0;
BA_ "GenSigSNA" SG_ 1173 UI_predictedEnergy "32768";
BA_ "Confidence" SG_ 1173 UI_hindsightEnergy 0;
BA_ "GenSigSNA" SG_ 1173 UI_hindsightEnergy "32768";
BA_ "Confidence" SG_ 764 VCSEAT2L_row2SeatStatusIndex 1;
BA_ "Confidence" SG_ 764 VCSEAT2L_seatTrackPosReal 0;
BA_ "Confidence" SG_ 764 VCSEAT2L_seatTrackPosOffset 0;
BA_ "Confidence" SG_ 764 VCSEAT2L_seatReclineState 0;
BA_ "GenSigSNA" SG_ 764 VCSEAT2L_seatReclineState "15";
BA_ "Confidence" SG_ 764 VCSEAT2L_seatReclineCalibrated 0;
BA_ "Confidence" SG_ 764 VCSEAT2L_seatReclinePositionStat 0;
BA_ "GenSigSNA" SG_ 764 VCSEAT2L_seatReclinePositionStat "4";
BA_ "SystemSignalLongSymbol" SG_ 764 VCSEAT2L_seatReclinePositionStat "VCSEAT2L_seatReclinePositionState";
BA_ "Confidence" SG_ 764 VCSEAT2L_seatReclineAbsPosS_0001 0;
BA_ "SystemSignalLongSymbol" SG_ 764 VCSEAT2L_seatReclineAbsPosS_0001 "VCSEAT2L_seatReclineAbsPosSwitchTransPoint";
BA_ "Confidence" SG_ 764 VCSEAT2L_seatReclineAbsPosSwitch 0;
BA_ "GenSigSNA" SG_ 764 VCSEAT2L_seatReclineAbsPosSwitch "0";
BA_ "SystemSignalLongSymbol" SG_ 764 VCSEAT2L_seatReclineAbsPosSwitch "VCSEAT2L_seatReclineAbsPosSwitchState";
BA_ "Confidence" SG_ 764 VCSEAT2L_seatReclineFoldAllowed 0;
BA_ "Confidence" SG_ 764 VCSEAT2L_seatReclineUnfoldAllowe 0;
BA_ "SystemSignalLongSymbol" SG_ 764 VCSEAT2L_seatReclineUnfoldAllowe "VCSEAT2L_seatReclineUnfoldAllowed";
BA_ "Confidence" SG_ 764 VCSEAT2L_seatReclineAdjustmentAl 0;
BA_ "SystemSignalLongSymbol" SG_ 764 VCSEAT2L_seatReclineAdjustmentAl "VCSEAT2L_seatReclineAdjustmentAllowed";
BA_ "Confidence" SG_ 764 VCSEAT2L_seat1RClashAvoidanceBlo 0;
BA_ "SystemSignalLongSymbol" SG_ 764 VCSEAT2L_seat1RClashAvoidanceBlo "VCSEAT2L_seat1RClashAvoidanceBlockedReason";
BA_ "Confidence" SG_ 764 VCSEAT2L_seat1RClashAvoidanceSta 0;
BA_ "SystemSignalLongSymbol" SG_ 764 VCSEAT2L_seat1RClashAvoidanceSta "VCSEAT2L_seat1RClashAvoidanceState";
BA_ "Confidence" SG_ 764 VCSEAT2L_seatReclineChoreoBlocke 0;
BA_ "SystemSignalLongSymbol" SG_ 764 VCSEAT2L_seatReclineChoreoBlocke "VCSEAT2L_seatReclineChoreoBlockedByOccupancy";
BA_ "Confidence" SG_ 764 VCSEAT2L_seatReclineNextToggleDi 0;
BA_ "GenSigSNA" SG_ 764 VCSEAT2L_seatReclineNextToggleDi "2";
BA_ "SystemSignalLongSymbol" SG_ 764 VCSEAT2L_seatReclineNextToggleDi "VCSEAT2L_seatReclineNextToggleDirection";
BA_ "Confidence" SG_ 1986 VCSEAT2L_seatStatus2Index 1;
BA_ "Confidence" SG_ 1986 VCSEAT2L_choreography2RState 0;
BA_ "Confidence" SG_ 1986 VCSEAT2L_choreography3RState 0;
BA_ "Confidence" SG_ 1986 VCSEAT2L_choreography1RIsAllowed 0;
BA_ "SystemSignalLongSymbol" SG_ 1986 VCSEAT2L_choreography1RIsAllowed "VCSEAT2L_choreography1RIsAllowedToMove";
BA_ "Confidence" SG_ 1986 VCSEAT2L_choreography2RIsAllowed 0;
BA_ "SystemSignalLongSymbol" SG_ 1986 VCSEAT2L_choreography2RIsAllowed "VCSEAT2L_choreography2RIsAllowedToMove";
BA_ "Confidence" SG_ 1986 VCSEAT2L_choreography1RTrackVelo 0;
BA_ "SystemSignalLongSymbol" SG_ 1986 VCSEAT2L_choreography1RTrackVelo "VCSEAT2L_choreography1RTrackVelocityType";
BA_ "Confidence" SG_ 1986 VCSEAT2L_choreography1RBackrestV 0;
BA_ "SystemSignalLongSymbol" SG_ 1986 VCSEAT2L_choreography1RBackrestV "VCSEAT2L_choreography1RBackrestVelocityType";
BA_ "Confidence" SG_ 1986 VCSEAT2L_choreography2RTrackVelo 0;
BA_ "SystemSignalLongSymbol" SG_ 1986 VCSEAT2L_choreography2RTrackVelo "VCSEAT2L_choreography2RTrackVelocityType";
BA_ "Confidence" SG_ 1986 VCSEAT2L_choreography2RBackrestV 0;
BA_ "SystemSignalLongSymbol" SG_ 1986 VCSEAT2L_choreography2RBackrestV "VCSEAT2L_choreography2RBackrestVelocityType";
BA_ "Confidence" SG_ 1986 VCSEAT2L_choreography3RBackrestV 0;
BA_ "SystemSignalLongSymbol" SG_ 1986 VCSEAT2L_choreography3RBackrestV "VCSEAT2L_choreography3RBackrestVelocityType";
BA_ "Confidence" SG_ 1986 VCSEAT2L_choreographyState 0;
BA_ "Confidence" SG_ 1986 VCSEAT2L_choreographyCollisionPa 0;
BA_ "SystemSignalLongSymbol" SG_ 1986 VCSEAT2L_choreographyCollisionPa "VCSEAT2L_choreographyCollisionPair";
BA_ "Confidence" SG_ 1986 VCSEAT2L_2rMovingForChoreography 0;
BA_ "Confidence" SG_ 746 VCSEAT2R_seatStatus2Index 1;
BA_ "Confidence" SG_ 746 VCSEAT2R_choreography2RState 0;
BA_ "Confidence" SG_ 746 VCSEAT2R_choreography3RState 0;
BA_ "Confidence" SG_ 746 VCSEAT2R_choreography1RIsAllowed 0;
BA_ "SystemSignalLongSymbol" SG_ 746 VCSEAT2R_choreography1RIsAllowed "VCSEAT2R_choreography1RIsAllowedToMove";
BA_ "Confidence" SG_ 746 VCSEAT2R_choreography2RIsAllowed 0;
BA_ "SystemSignalLongSymbol" SG_ 746 VCSEAT2R_choreography2RIsAllowed "VCSEAT2R_choreography2RIsAllowedToMove";
BA_ "Confidence" SG_ 746 VCSEAT2R_choreography1RTrackVelo 0;
BA_ "SystemSignalLongSymbol" SG_ 746 VCSEAT2R_choreography1RTrackVelo "VCSEAT2R_choreography1RTrackVelocityType";
BA_ "Confidence" SG_ 746 VCSEAT2R_choreography1RBackrestV 0;
BA_ "SystemSignalLongSymbol" SG_ 746 VCSEAT2R_choreography1RBackrestV "VCSEAT2R_choreography1RBackrestVelocityType";
BA_ "Confidence" SG_ 746 VCSEAT2R_choreography2RTrackVelo 0;
BA_ "SystemSignalLongSymbol" SG_ 746 VCSEAT2R_choreography2RTrackVelo "VCSEAT2R_choreography2RTrackVelocityType";
BA_ "Confidence" SG_ 746 VCSEAT2R_choreography2RBackrestV 0;
BA_ "SystemSignalLongSymbol" SG_ 746 VCSEAT2R_choreography2RBackrestV "VCSEAT2R_choreography2RBackrestVelocityType";
BA_ "Confidence" SG_ 746 VCSEAT2R_choreography3RBackrestV 0;
BA_ "SystemSignalLongSymbol" SG_ 746 VCSEAT2R_choreography3RBackrestV "VCSEAT2R_choreography3RBackrestVelocityType";
BA_ "Confidence" SG_ 746 VCSEAT2R_choreographyState 0;
BA_ "Confidence" SG_ 746 VCSEAT2R_choreographyCollisionPa 0;
BA_ "SystemSignalLongSymbol" SG_ 746 VCSEAT2R_choreographyCollisionPa "VCSEAT2R_choreographyCollisionPair";
BA_ "Confidence" SG_ 746 VCSEAT2R_2rMovingForChoreography 0;
VAL_ 1056 UIS_logMux 451 "CamViewerServiceEnabled" 450 "activeAppView" 449 "amdSocPkgPower" 448 "apeHardwareMinorVersion" 447 "audioA2BRediscoveryCount" 446 "audioMediaBrowsing" 445 "audioMediaPlaying" 444 "audioPWSGain" 443 "audioSource" 442 "audioState" 441 "audioType" 440 "audioVolumeLevel" 439 "backlightUserRequest" 438 "bifrostCPUUsage" 437 "bifrostMemUsage" 436 "bifrostOdinEngineRequests" 435 "bifrostOdinEngineUp" 434 "bluetoothAutoConnectionState" 433 "bluetoothAutoconnectActive" 432 "bluetoothAutoconnectAttempts" 431 "bluetoothCPUUsage" 430 "bluetoothConnectionState" 429 "bluetoothMemUsage" 428 "bluetoothPairResult" 427 "bluetoothStackRearState" 426 "bluetoothStackState" 425 "bluetoothState" 424 "boardTemperature" 423 "bootCount" 422 "camBackupDecodeAvgFrametime" 421 "camBackupDecodeFramecount" 420 "camBackupDecodeMaxFrametime" 419 "camBackupDecodeMinFrametime" 418 "cameraBackupFramerate" 417 "cameraBackupLateFrames" 416 "pmSuspendHookIndex" 415 "cameraBackupMaxFrametime" 414 "cameraBackupPacketState" 413 "cameraBackupPipeline" 412 "cameraBackupPopup" 411 "cameraBackupRenderState" 410 "cameraBackupStreamMissing" 409 "cameraBackupStreamQuality" 408 "cameraFrontPacketState" 407 "cameraFrontPipeline" 406 "cameraFrontPopup" 405 "cameraFrontRenderState" 404 "cameraFrontStreamMissing" 403 "cameraLDownwardPacketState" 402 "cameraLDownwardPipeline" 401 "cameraLDownwardRenderState" 400 "cameraLRepeaterFramerate" 399 "cameraLRepeaterLateFrames" 398 "cameraLRepeaterMaxFrametime" 397 "cameraLRepeaterPacketState" 396 "cameraLRepeaterPipeline" 395 "cameraLRepeaterPopup" 394 "cameraLRepeaterRenderState" 393 "cameraLRepeaterStreamMissing" 392 "cameraRDownwardPacketState" 391 "cameraRDownwardPipeline" 390 "cameraRDownwardRenderState" 389 "cameraRRepeaterFramerate" 388 "cameraRRepeaterLateFrames" 387 "cameraRRepeaterMaxFrametime" 386 "cameraRRepeaterPacketState" 385 "cameraRRepeaterPipeline" 384 "cameraRRepeaterPopup" 383 "cameraRRepeaterRenderState" 382 "cameraRRepeaterStreamMissing" 381 "cameraRearViewPacketState" 380 "cameraRearViewPipeline" 379 "cameraRearViewPopup" 378 "cameraRearViewRenderState" 377 "cameraRearViewStreamMissing" 376 "cameraSelectablePacketState" 375 "cameraSelectablePipeline" 374 "cameraSelectableRenderState" 373 "carAssistErrorCode" 372 "carAssistMicAlsaRms" 371 "carAssistMicMuted" 370 "carAssistSessionCount" 369 "carAssistState" 341 "cellularConnectivityStatus" 340 "cellularLinkManagerState" 339 "centerDispAsilA_lsb" 338 "centerDispAsilA_msb" 337 "centerDispAsilB_lsb" 336 "centerDispAsilB_msb" 335 "centerDisplayEvent" 334 "centerDisplayState" 333 "ceruleanx8664CPUUsage" 332 "ceruleanx8664MemUsage" 331 "chargeLocationId" 330 "chargeOnSolarNoChargeReason" 329 "chromiumadapterCPUUsage" 328 "chromiumadapterMemUsage" 327 "clusterCPUUsage" 326 "clusterDisplayState" 325 "clusterFramesOver100Ms" 324 "clusterFramesOver200Ms" 323 "clusterMaxFrametime" 322 "clusterMeanFPS" 321 "clusterMemUsage" 320 "cobaltlinuxCPUUsage" 319 "cobaltlinuxMemUsage" 318 "compositorFrameMonitorState" 317 "compositorRenderAvgRenderTime" 316 "compositorRenderFrameCount" 315 "compositorRenderFrameRate" 314 "compositorRenderGpuPercentage" 313 "compositorRenderMaxFrameTime" 312 "compositorRenderMaxRenderTime" 311 "compositorRenderMinFrameTime" 310 "compositorRenderMinRenderTime" 309 "connectedToInternet" 308 "cpuTemperature" 307 "dasAutonomyControlMessageMiaInDriverlessTakeover" 306 "dashcamOnboardAvailableMB" 305 "dashcamOnboardMB" 304 "dashcamOnboardSavePressCount" 303 "dashcamOnboardTransferCount" 302 "dashcamSavedToOnboardCount" 301 "dashcamSavedToSavedCount" 300 "dashcamSavedToSentryCount" 299 "dashcamState" 298 "dashcamStorageAvailableMB" 297 "dashcamStorageRecentMB" 296 "dashcamStorageSavedMB" 295 "dashcamStorageSentryMB" 294 "dashcamStorageState" 293 "dashcamTransferCount" 292 "dashcamTransferFileCount" 291 "dashcamTransferRateMBps" 290 "dashcamTransferSizeMB" 289 "dashcamTransferTimeMs" 288 "dashcamviewerCPUUsage" 287 "dashcamviewerMemUsage" 286 "developerMode" 285 "dgpuTemperature" 284 "dmCenterAsilCalibrationSync" 283 "dmCenterAsilFirmwareStatus" 282 "dmCenterAsilOpenFlag" 281 "dmCenterAsilResumeFlag" 280 "dmCenterAsilShortFlag" 279 "dmCenterBacklightControlDeferred" 278 "dmCenterBacklightDevExists" 277 "dmCenterBacklightDutyCycle" 276 "dmCenterBacklightFault" 275 "dmCenterBacklightNits" 274 "dmCenterBacklightPowerLevel" 273 "dmCenterConnected" 272 "dmCenterEnabled" 271 "dmCenterLinkCheckOk" 270 "dmCenterMOsdExactCrcCheck" 269 "dmCenterMOsdVideoCrcData" 268 "dmCenterModeSettingStatus" 267 "dmCenterOsdDayNightState" 266 "dmCenterOsdDisplayedState" 265 "dmCenterPowerState" 264 "dmCenterSOsdExactCrcCheck" 263 "dmCenterSOsdVideoCrcData" 262 "dmCenterTouchDeviceExists" 261 "dmCenterTouchIrqCount" 260 "dmGatewayLinkWedged" 259 "dmIcuAsilFirmwareStatus" 258 "dmIcuAsilOpenFlag" 257 "dmIcuAsilResumeFlag" 256 "dmIcuAsilShortFlag" 255 "dmIcuBacklightDevExists" 254 "dmIcuBacklightDutyCycle" 253 "dmIcuBacklightFault" 252 "dmIcuBacklightNits" 251 "dmIcuBacklightPowerLevel" 250 "dmIcuConnected" 249 "dmIcuEnabled" 248 "dmIcuLinkCheckOk" 247 "dmIcuPowerState" 246 "dmIcuTouchIrqCount" 245 "dmRearAsilStatusLsb" 244 "dmRearAsilStatusMsb" 243 "dmRearBacklightDevExists" 242 "dmRearBacklightDutyCycle" 241 "dmRearBacklightFault" 240 "dmRearBacklightNits" 239 "dmRearBacklightPowerLevel" 238 "dmRearConnected" 237 "dmRearEnabled" 236 "dmRearLinkCheckOk" 235 "dmRearPowerState" 234 "dmRearTouchDeviceExists" 233 "dumTclipClipCount" 232 "dumTclipSuccessfulUploadCount" 231 "dumTclipTransferCount" 230 "dumTclipUploadActive" 229 "dumTclipUploadState" 228 "dynamicTriggersCampaignState" 227 "dynamicTriggersHRLServiceState" 226 "dynamicTriggersOutputManagerServiceState" 225 "dynamicTriggersTelemetryServiceState" 224 "embeddedGameName" 223 "embeddedGameState" 222 "estimatedOccupancyCount" 221 "featureSuperchargingEnabled" 220 "firmwareReleaseScope" 219 "godotCPUUsage" 218 "godotMemUsage" 217 "godot_MEMORY_DYNAMIC" 216 "godot_MEMORY_STATIC" 215 "godot_TIME_FPS" 214 "godot_TIME_PROCESS" 213 "gpsmanagerCPUUsage" 212 "gpsmanagerMemUsage" 211 "gtwSocUartRxStatBadChecksum" 210 "gtwSocUartRxStatBadTooBig" 209 "gtwSocUartRxStatBadTooSmall" 208 "gtwSocUartRxStatHandleErr" 207 "gtwSocUartRxStatHeartbeats" 206 "gtwSocUartRxStatMsgErr" 205 "gtwSocUartRxStatUnhandled" 204 "gtwSocUartRxStatValidPackets" 203 "gtwSocUartTxStatAnsMismatch" 202 "gtwSocUartTxStatBadTooBig" 201 "gtwSocUartTxStatNacks" 200 "gtwSocUartTxStatPackets" 199 "gtwSocUartTxStatTimeouts" 198 "headsetConnectionState" 197 "headsetPairResult" 196 "hermesclientCPUUsage" 195 "hermesclientMemUsage" 194 "hermesdynamicCPUUsage" 193 "hermesdynamicMemUsage" 192 "hicarAudioSetupState" 191 "hicarAudioTeardownState" 190 "hicarCallState" 189 "hicarConnectionState" 188 "hicarDataReceiveType" 187 "hicarErrorCode" 186 "hicarEventCode" 185 "hicarServiceState" 184 "homelinkState" 183 "igpuTemperature" 182 "inSuperchargerGeofence" 181 "limex8664CPUUsage" 180 "limex8664MemUsage" 179 "mediaImageCacheCost" 178 "mediaImageCacheSize" 177 "mediaNeedAuthToken" 176 "mediaPlaybackStatus" 175 "mediaserveCPUUsage" 174 "mediaserveMemUsage" 173 "mirrorGeofenceActive" 172 "modemBusyActive" 171 "modemECallppAvail" 170 "mounterdDashcamCapacityGB" 169 "mounterdDeviceCount" 168 "mounterdEncryptionCapacityGB" 167 "mounterdFilesystemCountExfat" 166 "mounterdFilesystemCountExt3" 165 "mounterdFilesystemCountExt4" 164 "mounterdFilesystemCountFat32" 163 "mounterdFrontHubConnected" 162 "mounterdFrontHubDisconnected" 161 "mounterdMountCountTotal" 160 "mounterdState" 159 "muteNavVolume" 158 "navAudioVolume" 157 "navServiceError" 156 "netCellRxCount" 155 "netCellRxRate" 154 "netCellTxCount" 153 "netCellTxRate" 152 "netEthRxCount" 151 "netEthRxDroppedCount" 150 "netEthRxDroppedRate" 149 "netEthRxErrorCount" 148 "netEthRxErrorRate" 147 "netEthRxRate" 146 "netEthTxCount" 145 "netEthTxRate" 144 "netWifiRxCount" 143 "netWifiRxRate" 142 "netWifiTxCount" 141 "netWifiTxRate" 140 "nuanceserverCPUUsage" 139 "nuanceserverMemUsage" 138 "numCorrMemErrorsECC" 137 "numUncorrMemErrorsECC" 136 "nvmeDataUnitsWritten100mb" 135 "nvmePercentLifetimeUsed" 134 "nvmeTemperature" 133 "odinAuthCount" 132 "odinAuthFailCount" 131 "odinCPUUsage" 130 "odinEcuLogForceTriggerUploadState" 129 "odinEcuLogUploadState" 128 "odinFileSystemState" 127 "odinGatewayConnectionState" 126 "odinHermesConnectionState" 125 "odinHrlLogUploadState" 124 "odinHrlUploadLimits" 123 "odinListTasksCmdDurationMs" 122 "odinListTasksCmdResult" 121 "odinMemUsage" 120 "odinNetworkFailCount" 119 "odinNetworkStartCount" 118 "odinOrchestratorFailCount" 117 "odinOrchestratorStartCount" 116 "odinPeriodicTaskState" 115 "odinProcessState" 114 "odinStatusCmdDurationMs" 113 "odinStatusCmdResult" 112 "polytopiax8664CPUUsage" 111 "polytopiax8664MemUsage" 110 "powerManagerState" 109 "psiCpuSome" 108 "psiIOFull" 107 "psiIOSome" 106 "psiMemFull" 105 "psiMemSome" 104 "qtcarCPUUsage" 103 "qtcarMemUsage" 102 "radioserveCPUUsage" 101 "radioserveMemUsage" 100 "rearDisplayState" 99 "rearDisplayUserPresent" 98 "releasenotesCPUUsage" 97 "releasenotesMemUsage" 96 "remoteRequestType" 95 "robotaxiModeActive" 94 "scheduleChargeEndTime" 93 "scheduleChargeStartTime" 92 "scheduledChargingMode" 91 "sentryIncidentCount" 90 "sentryNeedsNap" 89 "sentryState" 88 "serverCPUUsage" 87 "serverMemUsage" 86 "serviceMode" 85 "serviceModePlus" 84 "settingsAutoTurnSignal" 83 "slackerLoginResult" 82 "sleepCount" 81 "sleepState" 80 "sleepTime" 79 "sleepType" 78 "softwareInstallPopupStatus" 77 "softwareUpdatePrimDownload" 76 "softwareUpdateState" 75 "solitaireCPUUsage" 74 "solitaireMemUsage" 73 "speechrecoCPUUsage" 72 "speechrecoMemUsage" 71 "spotifyserverCPUUsage" 70 "spotifyserverMemUsage" 69 "sudokuCPUUsage" 68 "sudokuMemUsage" 67 "superchargePaymentNeeded" 66 "suspensionGeofence" 65 "systemMemSwapUsage" 64 "systemUptime" 63 "systemWakeTime" 62 "tegraModemManState" 61 "teleopAvgPacketDelta" 60 "teleopMaxPacketDelta" 59 "teleopMinPacketDelta" 58 "teleopPacketDrops" 57 "teleopPhoneCallActive" 56 "teleopStreamXrunCount" 55 "teslaMediaCacheCost" 54 "teslaMediaCacheSize" 53 "teslachromiumCPUUsage" 52 "teslachromiumMemUsage" 51 "testDriveMode" 50 "thermalProfile" 49 "thermalResistance" 48 "tmserverCPUUsage" 47 "tmserverMemUsage" 46 "touchEventsAggCount" 45 "tunerCurrentAntenna1" 44 "tunerCurrentAntenna2" 43 "tunerTemperatureCelsius" 42 "tunerTemperatureFahrenheit" 41 "tunerVoltage1V8" 40 "tunerVoltage3V3" 39 "tunerVoltageAntenna1" 38 "tunerVoltageAntenna2" 37 "tunerVoltageMQS" 36 "tunerVoltageOperation" 35 "tunerVoltageUBatt" 34 "uiFramesOver100Ms" 33 "uiFramesOver200Ms" 32 "uiFrametimeGearShiftDToR" 31 "uiFrametimeGearShiftPToR" 30 "uiMaxFrametime" 29 "uiMeanFPS" 28 "uiQtCarSwapUsage" 27 "uiQtCarUptime" 26 "valetMode" 25 "valhallaserverCPUUsage" 24 "valhallaserverMemUsage" 23 "vehicleCPUUsage" 22 "vehicleMemUsage" 21 "videodCPUUsage" 20 "videodMemUsage" 19 "vmtouchCPUUsage" 18 "vmtouchMemUsage" 17 "webbrowserCPUUsage" 16 "webbrowserMemUsage" 15 "wifiAutoJoinLowRSSI" 14 "wifiBars" 13 "wifiStackReady" 12 "wifiStackState" 11 "wifiTemperature" 10 "zramCompressedSize" 9 "zramCompressionRatio" 8 "zramFailedReads" 7 "zramFailedWrites" 6 "zramInvalidIO" 5 "zramNotifyFree" 4 "zramOriginalSize" 3 "zramReadIO" 2 "zramReadTicks" 1 "zramWriteIO" 0 "zramWriteTicks" ;
VAL_ 1056 UIS_wifiStackState 17 "WL_RESET_CONNMAN" 16 "WL_RUNNING_LOCAL" 15 "WL_CAPTIVE" 14 "WL_DISCONNECTING" 13 "WL_RUNNING" 12 "WL_WAITING_ONLINE" 11 "WL_CHECKING" 10 "WL_CONFIGURING" 9 "WL_CONNECTING" 8 "WL_SELECTING_NETWORK" 7 "WL_WAITING_AUTOCONNECT" 6 "WL_SEARCHING" 5 "WL_POWERING_ON" 4 "WL_DISABLED_WAIT" 3 "WL_POWERING_OFF" 2 "WL_WAITING_TECHNOLOGY" 1 "WL_RESETTING" 0 "DEFAULT" ;
VAL_ 1056 UIS_wifiAutoJoinLowRSSI 1 "TRUE" 0 "FALSE" ;
VAL_ 1056 UIS_valetMode 1 "TRUE" 0 "FALSE" ;
VAL_ 1056 UIS_tegraModemManState 20 "INVALID" 19 "CHECKINGMODEM" 18 "CHECKINGPORTS" 17 "STOPPINGLINK" 16 "UNCONFIGURINGLINK" 15 "RUNNINGSTATUS" 14 "RUNNING" 13 "CHECKINGLINK" 12 "CONFIGURINGLINK" 11 "RETRYINGLINK" 10 "STARTINLINK" 9 "PRECONDITIONINGLINK" 8 "INITIALIZING2" 7 "CHECKINGANTENNA" 6 "ENABLINGSIM" 5 "INITIALIZING1" 4 "RECOVERING" 3 "WAKING" 2 "SLEEPING" 1 "RESTARTING" 0 "ABORTINGLINK" ;
VAL_ 1056 UIS_suspensionGeofence 1 "REQUESTED" 0 "REMOVED" ;
VAL_ 1056 UIS_sleepType 4 "Unknown" 3 "ModernStandby" 2 "S2Idle" 1 "S3" 0 "Shallow" ;
VAL_ 1056 UIS_sleepState 3 "Wake" 2 "Sleep" 1 "Run" 0 "Boot" ;
VAL_ 1056 UIS_slackerLoginResult 5000 "SLACKER_LOGIN_CREDENTIALS_MISSING" 444 "SLACKER_LOGIN_USER_BUMPED" 412 "SLACKER_LOGIN_TOKEN_INVALID_TIMESTAMP" 409 "SLACKER_LOGIN_TOKEN_REVOKED_KEY" 403 "SLACKER_LOGIN_CAPTCHA_REQUIRED" 401 "SLACKER_LOGIN_INCORRECT_CREDENTIALS" 400 "SLACKER_LOGIN_TOKEN_INVALID_SIGNATURE" 6 "SLACKER_LOGIN_BAD_ACCOUNT_LEVEL" 5 "SLACKER_LOGIN_OTHER_ERROR" 4 "SLACKER_LOGIN_NET_ERROR" 3 "SLACKER_LOGIN_TOKEN_UNKNOWN_ERROR" 2 "SLACKER_LOGIN_SUCCESS" 1 "SLACKER_LOGIN_SERVERTIME_FAILED" ;
VAL_ 1056 UIS_sentryState 5 "QUIET" 4 "PANIC" 3 "AWARE" 2 "ARMED" 1 "IDLE" 0 "OFF" ;
VAL_ 1056 UIS_scheduledChargingMode 3 "TIME_WINDOW" 2 "END_BY" 1 "START_AT" 0 "OFF" ;
VAL_ 1056 UIS_remoteRequestType 106 "NAV_GPS_DESTINATION_REQUEST" 105 "TESLA_AUTH_RESPONSE" 104 "GET_MESSAGE" 103 "SET_LIGHTBAR_DITCH" 102 "SET_LIGHTBAR_MIDDLE" 101 "SET_LIGHTBAR_BRIGHTNESS" 100 "REMOVE_PRECONDITION_SCHEDULE" 99 "ADD_PRECONDITION_SCHEDULE" 98 "REMOVE_CHARGE_SCHEDULE" 97 "ADD_CHARGE_SCHEDULE" 96 "SET_REAR_ZONE_LIGHT_REQUEST" 95 "SET_FRONT_ZONE_LIGHT_REQUEST" 94 "SET_TENT_MODE_REQUEST" 93 "SET_POWERSHARE_REQUEST" 92 "SET_POWERSHARE_DISCHARGE_LIMIT" 91 "SET_POWERSHARE_FEATURE" 90 "NAVIGATION_WAYPOINTS_REQUEST" 89 "VEHICLE_CONTROL_RESET_PIN_TO_DRIVE_ADMIN" 88 "SET_TRUCK_BED_LIGHT_BRIGHTNESS" 87 "SET_TRUCK_BED_LIGHT_AUTO_STATE" 86 "SET_TRAILER_LIGHT_TEST_START_STOP" 85 "SET_POWER_FEED_SOC_LIMIT" 84 "SET_POWER_FEED_TIMER" 83 "SET_POWER_FEED_ON_OFF" 82 "SET_OUTLET_SOC_LIMIT" 81 "SET_OUTLET_TIMER" 80 "SET_OUTLETS_ON_OFF" 79 "DRIVING_CLEAR_SPEED_LIMIT_PIN_ADMIN" 78 "VEHICLE_CONTROL_RESET_PIN_TO_DRIVE" 77 "VEHICLE_CONTROL_SET_PIN_TO_DRIVE" 76 "RESERVED_SEVENTY_SIX" 75 "GET_CHARGE_ON_SOLAR_FEATURE" 74 "UPDATE_CHARGE_ON_SOLAR_FEATURE" 73 "GET_MANAGED_CHARGING_SITES" 72 "ERASE_USER_DATA" 71 "STW_HEAT_LEVEL" 70 "AUTO_STW_HEAT" 69 "NAVIGATION_ROUTE" 68 "REMOVE_MANAGED_CHARGING_SITE" 67 "ADD_MANAGED_CHARGING_SITE" 66 "SET_COP_TEMP" 65 "GUEST_MODE" 64 "BOOMBOX" 63 "BLUETOOTH_CLASSIC_PAIRING_REQUEST" 62 "CHARGE_PORT_DOOR_OPEN" 61 "CHARGE_PORT_DOOR_CLOSE" 60 "RESERVED_SIXTY" 59 "RESERVED_FIFTY_NINE" 58 "TAKE_DRIVENOTE" 57 "VIDEO_REQUEST" 56 "GET_RATE_TARIFF" 55 "RESERVED_FIFTY_FIVE" 54 "SET_VEHICLE_NAME" 53 "NAVIGATION_GPS_REQUEST" 52 "PSEUDONYM_SYNC_REQUEST" 51 "PII_KEY_REQUEST" 50 "SET_CABIN_OVERHEAT_PROTECTION" 49 "HVAC_SEAT_COOLER_ACTIONS" 48 "AUTO_SEAT_CLIMATE" 47 "DASHCAM_SAVE_CLIP" 46 "PING" 45 "HVAC_RECIRCULATION" 44 "HVAC_CLIMATE_KEEPER" 43 "SET_CHARGING_AMPS" 42 "SCHEDULED_DEPARTURE" 41 "SCHEDULED_CHARGING" 40 "VITALS_ACK" 39 "VITALS_SUBSCRIPTION" 38 "VEHICLE_DATA_ACK" 37 "VEHICLE_DATA_SUBSCRIPTION" 36 "HVAC_SEAT_HEATER_ACTIONS" 35 "HVAC_BIO_WEAPON_MODE" 34 "VEHICLE_CONTROL_WINDOW" 33 "VEHICLE_CONTROL_TRIGGER_HOMELINK" 32 "VEHICLE_CONTROL_SUNROOF_OPEN_CLOSE" 31 "VEHICLE_CONTROL_SET_VALET_MODE" 30 "VEHICLE_CONTROL_SET_SENTRY_MODE" 29 "VEHICLE_CONTROL_SCHEDULE_SOFTWARE_UPDATE" 28 "VEHICLE_CONTROL_RESET_VALET_PIN" 27 "VEHICLE_CONTROL_HONK_HORN" 26 "VEHICLE_CONTROL_FLASH_LIGHTS" 25 "VEHICLE_CONTROL_CANCEL_SOFTWARE_UPDATE" 24 "UI_SET_UPCOMING_CALENDAR_ENTRIES" 23 "GET_NEARBY_CHARGING_SITES" 22 "NAVIGATION_SUPERCHARGER_REQUEST" 21 "NAVIGATION_REQUEST" 20 "MEDIA_PREVIOUS_TRACK" 19 "MEDIA_NEXT_TRACK" 18 "MEDIA_PREVIOUS_FAVORITE" 17 "MEDIA_NEXT_FAVORITE" 16 "MEDIA_UPDATE_VOLUME" 15 "MEDIA_PLAY" 14 "HVAC_TEMPERATURE_ADJUSTMENT" 13 "HVAC_STEERING_WHEEL_HEATER" 12 "HVAC_SET_PRECONDITIONING_MAX" 11 "RESERVED_ELEVEN" 10 "HVAC_AUTO" 9 "DRIVING_SPEED_LIMIT" 8 "DRIVING_SET_SPEED_LIMIT" 7 "DRIVING_CLEAR_SPEED_LIMIT_PIN" 6 "CHARGING_START_STOP" 5 "CHARGING_SET_LIMIT" 4 "STREAM_MESSAGE" 3 "CREATE_STREAM_SESSION" 2 "REMOTE_START_DRIVE" 1 "GET_VEHICLE_DATA" 0 "UNKNOWN" ;
VAL_ 1056 UIS_rearDisplayUserPresent 1 "TRUE" 0 "FALSE" ;
VAL_ 1056 UIS_rearDisplayState 9 "ENTERTAINMENT" 8 "DOG" 7 "SENTRY" 6 "LOCK" 5 "CHARGING" 4 "DRIVING" 3 "ON" 2 "ACCESSORY" 1 "DIM" 0 "OFF" ;
VAL_ 1056 UIS_powerManagerState 31 "PMS_ENTERINGROBOTAXILOADSHED" 30 "PMS_ROBOTAXILOADSHEDDING" 29 "PMS_UPLOADDATA" 28 "PMS_EXTREMELOADSHEDDING" 27 "PMS_ENTERINGEXTREMELOADSHED" 26 "PMS_PREPARINGSLEEP" 25 "PMS_ENTERINGLOADSHED" 24 "PMS_SENTRYACTIVE" 23 "PMS_EXITINGLOADSHED" 22 "PMS_LOADSHEDDING" 21 "PMS_EXITINGSENTRY" 20 "PMS_SENTRYARMED" 19 "PMS_ENTERINGSENTRY" 18 "PMS_UNKNOWN_SNA" 17 "PMS_EXITINGSLEEP" 16 "PMS_READYFORSLEEP" 15 "PMS_WAITINGONRAILS" 14 "PMS_PERFORMANCE" 13 "PMS_HIGHPOWERSTARTED" 12 "PMS_HIGHPOWERSTOPPING" 11 "PMS_HIGHPOWERSTARTING" 10 "PMS_REBOOT" 9 "PMS_ENTERINGSLEEP" 8 "PMS_ALLTUCKEDIN" 7 "PMS_CHARGING" 6 "PMS_AUDIOSTOPPED" 5 "PMS_AUDIOSTOPPING" 4 "PMS_POWERBROWNOUT" 3 "PMS_AUDIOSTARTING" 2 "PMS_ACCDELAY" 1 "PMS_FULLPOWER" 0 "PMS_CHECKING" ;
VAL_ 1056 UIS_modemECallppAvail 1 "ENABLED" 0 "DISABLED" ;
VAL_ 1056 UIS_modemBusyActive 1 "RUNNING" 0 "OFF" ;
VAL_ 1056 UIS_mirrorGeofenceActive 1 "TRUE" 0 "FALSE" ;
VAL_ 1056 UIS_mediaPlaybackStatus 2 "PAUSED" 1 "PLAYING" 0 "STOPPED" ;
VAL_ 1056 UIS_mediaNeedAuthToken 1 "TRUE" 0 "FALSE" ;
VAL_ 1056 UIS_inSuperchargerGeofence 1 "TRUE" 0 "FALSE" ;
VAL_ 1056 UIS_homelinkState 23 "HW_ERROR" 22 "UNIVERSAL_RECEIVER_ERROR" 21 "UNIVERSAL_RECEIVER_SUCCESS" 20 "UNIVERSAL_RECEIVER_WAIT" 19 "DEFAULT_FAIL" 18 "DEFAULT_SUCCESS" 17 "DEFAULT_WAIT" 16 "STANDARD_FAIL" 15 "STANDARD_SUCCESS" 14 "STANDARD_WAIT" 13 "CLEAR_FAIL" 12 "CLEAR_SUCCESS" 11 "CLEAR_WAIT" 10 "TIMEOUT" 9 "LEARN_FAIL" 8 "LEARN_CANCLE" 7 "LEARN_SUCCESS_NOT_ROLLING" 6 "LEARN_SUCCESS_ROLLING" 5 "LEARN_TEST" 4 "LEARN_SUCCESS" 3 "LEARN_WAIT" 2 "PROGRAM_WAIT" 1 "TRANSMITTING" 0 "IDLE" ;
VAL_ 1056 UIS_headsetPairResult 23 "HID_PAIRED" 22 "HID_MAX_NR_OF_CONNS" 21 "HID_PAGE_TIMEOUT" 20 "HID_OETC_USER" 19 "HID_REJ_BY_REMOTE_NO_RES" 18 "HID_LMP_RESPONSE_TIMEOUT" 17 "HID_AUTH_FAILURE" 16 "HID_KEY_MISSING" 15 "HID_NO_RESPONSE" 14 "HID_ALREADY_REQUESTED_BY_REMOTE" 13 "HID_UNKNOWN" 12 "HID_UNPAIRED" 11 "PAIRED" 10 "MAX_NR_OF_CONNS" 9 "PAGE_TIMEOUT" 8 "OETC_USER" 7 "REJ_BY_REMOTE_NO_RES" 6 "LMP_RESPONSE_TIMEOUT" 5 "AUTH_FAILURE" 4 "KEY_MISSING" 3 "NO_RESPONSE" 2 "ALREADY_REQUESTED_BY_REMOTE" 1 "UNKNOWN" 0 "UNPAIRED" ;
VAL_ 1056 UIS_headsetConnectionState 77 "HID_ERROR_UNKNOWN" 76 "HID_ERROR_ANTENNA_DISCONNECTED" 75 "HID_CONNECTED" 74 "HID_CONNECT_CANCELLED" 73 "HID_CONNECT_PROFILE_UNAVAILABLE" 72 "HID_CONNECT_INVALID_ARGUMENT" 71 "HID_CONNECT_ADAPTER_OFF" 70 "HID_CONNECT_NOT_SUPPORTED" 69 "HID_CONNECT_ALREADY_CONN" 68 "HID_CONNECT_DEVICE_NOT_FOUND_NO_RESOURCES" 67 "HID_CONNECT_DEVICE_NOT_FOUND_PAGE_TIMEOUT" 66 "HID_CONNECT_DEVICE_NOT_FOUND" 65 "HID_CONNECT_FAILED_REMOTE_TERMINATED" 64 "HID_CONNECT_FAILED_NO_RESOURCES" 63 "HID_CONNECT_FAILED_CONNECTION_TIMEOUT" 62 "HID_CONNECT_FAILED" 61 "HID_CONNECT_SDP_FAILURE" 60 "HID_CONNECT_PIN_MISSING" 59 "HID_CONNECT_PAGE_TIMEOUT" 58 "HID_CONNECT_REJ_BY_REMOTE_NO_RES" 57 "HID_CONNECT_MAX_NR_OF_CONNS" 56 "HID_CONNECT_CONTROLLER_BUSY" 55 "HID_CONNECT_CONN_TIMEOUT" 54 "HID_CONNECT_MAX_NR_OF_ACL" 53 "HID_CONNECT_LMP_RESPONSE_TIMEOUT" 52 "HID_CONNECT_HOST_TIMEOUT" 51 "HID_CONNECT_UNKNOWN_FAILURE" 50 "HID_DISCONNECT_UNKNOWN" 49 "HID_DISCONNECT_OETC_POWERING_OFF" 48 "HID_DISCONNECT_OETC_LOW_RESOURCE" 47 "HID_DISCONNECT_REJ_BY_REMOTE_SEC" 46 "HID_DISCONNECT_AUTH_FAIL" 45 "HID_DISCONNECT_LMP_RESPONSE_TIMEOUT" 44 "HID_DISCONNECT_OETC_USER" 43 "HID_DISCONNECT_CONN_TIMEOUT" 42 "HID_DISCONNECT_CONN_TERM_LOCAL_HOST" 41 "HID_DISCONNECT_LINKLOSS" 40 "HID_DISCONNECT_FROM_REMOTE" 39 "HID_DISCONNECTED" 38 "ERROR_UNKNOWN" 37 "ERROR_ANTENNA_DISCONNECTED" 36 "CONNECTED" 35 "CONNECT_CANCELLED" 34 "CONNECT_PROFILE_UNAVAILABLE" 33 "CONNECT_INVALID_ARGUMENT" 32 "CONNECT_ADAPTER_OFF" 31 "CONNECT_NOT_SUPPORTED" 30 "CONNECT_ALREADY_CONN" 29 "CONNECT_DEVICE_NOT_FOUND_NO_RESOURCES" 28 "CONNECT_DEVICE_NOT_FOUND_PAGE_TIMEOUT" 27 "CONNECT_DEVICE_NOT_FOUND" 26 "CONNECT_FAILED_REMOTE_TERMINATED" 25 "CONNECT_FAILED_NO_RESOURCES" 24 "CONNECT_FAILED_CONNECTION_TIMEOUT" 23 "CONNECT_FAILED" 22 "CONNECT_SDP_FAILURE" 21 "CONNECT_PIN_MISSING" 20 "CONNECT_PAGE_TIMEOUT" 19 "CONNECT_REJ_BY_REMOTE_NO_RES" 18 "CONNECT_MAX_NR_OF_CONNS" 17 "CONNECT_CONTROLLER_BUSY" 16 "CONNECT_CONN_TIMEOUT" 15 "CONNECT_MAX_NR_OF_ACL" 14 "CONNECT_LMP_RESPONSE_TIMEOUT" 13 "CONNECT_HOST_TIMEOUT" 12 "CONNECT_UNKNOWN_FAILURE" 11 "DISCONNECT_UNKNOWN" 10 "DISCONNECT_OETC_POWERING_OFF" 9 "DISCONNECT_OETC_LOW_RESOURCE" 8 "DISCONNECT_REJ_BY_REMOTE_SEC" 7 "DISCONNECT_AUTH_FAIL" 6 "DISCONNECT_LMP_RESPONSE_TIMEOUT" 5 "DISCONNECT_OETC_USER" 4 "DISCONNECT_CONN_TIMEOUT" 3 "DISCONNECT_CONN_TERM_LOCAL_HOST" 2 "DISCONNECT_LINKLOSS" 1 "DISCONNECT_FROM_REMOTE" 0 "DISCONNECTED" ;
VAL_ 1056 UIS_dmRearPowerState 1 "ON" 0 "OFF" ;
VAL_ 1056 UIS_dmRearLinkCheckOk 1 "PASSED" 0 "FAILED" ;
VAL_ 1056 UIS_dmRearBacklightDevExists 1 "PASSED" 0 "FAILED" ;
VAL_ 1056 UIS_dmIcuPowerState 1 "ON" 0 "OFF" ;
VAL_ 1056 UIS_dmIcuLinkCheckOk 1 "PASSED" 0 "FAILED" ;
VAL_ 1056 UIS_dmIcuBacklightDevExists 1 "PASSED" 0 "FAILED" ;
VAL_ 1056 UIS_dmCenterPowerState 1 "ON" 0 "OFF" ;
VAL_ 1056 UIS_dmCenterOsdDisplayedState 1 "SHOWING" 0 "HIDDEN" ;
VAL_ 1056 UIS_dmCenterLinkCheckOk 1 "PASSED" 0 "FAILED" ;
VAL_ 1056 UIS_dmCenterBacklightPowerLevel 2 "HIGH_POWER" 1 "LOW_POWER" 0 "OFF" ;
VAL_ 1056 UIS_dmCenterBacklightDevExists 1 "PASSED" 0 "FAILED" ;
VAL_ 1056 UIS_dashcamStorageState 8 "RECENT_BUFFER_DURATION_REDUCED" 7 "SLOW" 6 "READ_ONLY" 5 "FULL" 4 "GETTING_FULL" 3 "ERROR" 2 "READY" 1 "REMOVED" 0 "INVALID" ;
VAL_ 1056 UIS_dashcamState 7 "STREAMING" 6 "SAVING" 5 "PAUSED" 4 "RECORDING" 3 "STOPPED" 2 "ERROR" 1 "TERMINATED" 0 "INVALID" ;
VAL_ 1056 UIS_clusterDisplayState 9 "ENTERTAINMENT" 8 "DOG" 7 "SENTRY" 6 "LOCK" 5 "CHARGING" 4 "DRIVING" 3 "ON" 2 "ACCESSORY" 1 "DIM" 0 "OFF" ;
VAL_ 1056 UIS_chargeOnSolarNoChargeReason 3 "ALTERNATIVE_VEHICLE_CHARGE_PRIORITY" 2 "GRID_EXPORT_PRIORITY" 1 "POWERWALL_CHRAGE_PRIORITY" 0 "INSUFFICIENT_SOLAR" ;
VAL_ 1056 UIS_centerDisplayState 9 "ENTERTAINMENT" 8 "DOG" 7 "SENTRY" 6 "LOCK" 5 "CHARGING" 4 "DRIVING" 3 "ON" 2 "ACCESSORY" 1 "DIM" 0 "OFF" ;
VAL_ 1056 UIS_centerDisplayEvent 21 "CPD_TRIGGERED" 20 "CAR_LOCKED" 19 "ENTERTAINMENT_OFF" 18 "ALL_STATES_EXCEPT_ENTERTAINMENT_TURNED_ON" 17 "IC_HAZARDS_OFF_DOOR_CLOSED_NO_OCCUPANTS" 16 "IC_HAZARDS_ON" 15 "ALL_DOORS_CLOSED_NO_OCCUPANTS_CHARGE_ACTIVE" 14 "TIMEOUT" 13 "DOOR_HANDLE_PULLED" 12 "ALL_STATES_EXCEPT_SENTRY" 11 "SENTRY_PANIC_ENDED" 10 "POWER_OFF_REQUEST" 9 "DRIVE_RAIL_OFF_NO_DRIVER_PRESENT" 8 "DRIVE_RAIL_OFF_DOOR_OPEN" 7 "DRIVE_RAIL_OFF_DRIVE_PRESENT" 6 "POWER_ON_REQUEST" 5 "DOOR_OPENED" 4 "ALL_STATES_EXCEPT_ENTERTAINMENT_DRIVE_RAIL_TURNED_ON" 3 "ALL_DOORS_CLOSED_NO_OCCUPANTS" 2 "PASSED_SPEED_THRESHOLD" 1 "SHIFTED_P_TO_N" 0 "OTHER" ;
VAL_ 1056 UIS_cellularLinkManagerState 16 "INVALID" 15 "RUNNING" 14 "DISCONNECTING" 13 "ROAMINGDISALLOWED" 12 "ENTERINGAIRPLANEMODE" 11 "CHECKING" 10 "RETRYING" 9 "CONFIGURING" 8 "CONNECTING" 7 "OFONOMODEMRELOADING" 6 "SEARCHING" 5 "CONFIGURINGAPN" 4 "QUERYDIAGNOSTIC" 3 "STARTING" 2 "UPDATING" 1 "RESETTING" 0 "RECOVERING" ;
VAL_ 1056 UIS_cellularConnectivityStatus 1 "CONNECTED" 0 "DISCONNECTED" ;
VAL_ 1056 UIS_carAssistState 5 "GROK" 4 "DICTATION" 3 "COMMAND" 2 "ERROR" 1 "IDLE" 0 "DISABLED" ;
VAL_ 1056 UIS_carAssistMicMuted 1 "TRUE" 0 "FALSE" ;
VAL_ 1056 UIS_carAssistErrorCode 17 "CLIENT_LOGGED_OUT_TOKEN_EXPIRED" 16 "CLIENT_PROVIDER_RATE_LIMTED" 15 "CLIENT_PROVIDER_AT_CAPACITY" 14 "CLIENT_ANON_USAGE_LIMITED" 13 "CLIENT_PREM_CONN" 12 "CLIENT_SPEECH" 11 "CLIENT_REMOTE" 10 "CLIENT_DBUS" 9 "CLIENT_DISCONNECTED" 8 "CLIENT_CONNECTIVITY" 7 "CLIENT_AUDIO" 6 "CLIENT_ERROR" 5 "COMMAND_NOT_IMPLEMENTED" 4 "COMMAND_NOT_AVAILABLE" 3 "COMMAND_NOT_UNDERSTOOD" 2 "REMOTE_ERROR" 1 "REMOTE_UNKNOWN" 0 "NONE" ;
VAL_ 1056 UIS_cameraSelectableRenderState 2 "ACTIVE" 1 "REQUESTED" 0 "INACTIVE" ;
VAL_ 1056 UIS_cameraSelectablePipeline 4 "PLAYING" 3 "PAUSED" 2 "READY" 1 "NULL" 0 "SLEEP" ;
VAL_ 1056 UIS_cameraSelectablePacketState 2 "RECEIVING" 1 "MISSING" 0 "CHECKING" ;
VAL_ 1056 UIS_cameraRearViewRenderState 2 "ACTIVE" 1 "REQUESTED" 0 "INACTIVE" ;
VAL_ 1056 UIS_cameraRearViewPacketState 2 "RECEIVING" 1 "MISSING" 0 "CHECKING" ;
VAL_ 1056 UIS_cameraRRepeaterStreamMissing 1 "MISSING" 0 "ACTIVE" ;
VAL_ 1056 UIS_cameraRRepeaterRenderState 2 "ACTIVE" 1 "REQUESTED" 0 "INACTIVE" ;
VAL_ 1056 UIS_cameraRRepeaterPopup 1 "OPEN" 0 "CLOSED" ;
VAL_ 1056 UIS_cameraRRepeaterPipeline 4 "PLAYING" 3 "PAUSED" 2 "READY" 1 "NULL" 0 "SLEEP" ;
VAL_ 1056 UIS_cameraRRepeaterPacketState 2 "RECEIVING" 1 "MISSING" 0 "CHECKING" ;
VAL_ 1056 UIS_cameraRDownwardRenderState 2 "ACTIVE" 1 "REQUESTED" 0 "INACTIVE" ;
VAL_ 1056 UIS_cameraRDownwardPacketState 2 "RECEIVING" 1 "MISSING" 0 "CHECKING" ;
VAL_ 1056 UIS_cameraLRepeaterStreamMissing 1 "MISSING" 0 "ACTIVE" ;
VAL_ 1056 UIS_cameraLRepeaterRenderState 2 "ACTIVE" 1 "REQUESTED" 0 "INACTIVE" ;
VAL_ 1056 UIS_cameraLRepeaterPopup 1 "OPEN" 0 "CLOSED" ;
VAL_ 1056 UIS_cameraLRepeaterPipeline 4 "PLAYING" 3 "PAUSED" 2 "READY" 1 "NULL" 0 "SLEEP" ;
VAL_ 1056 UIS_cameraLRepeaterPacketState 2 "RECEIVING" 1 "MISSING" 0 "CHECKING" ;
VAL_ 1056 UIS_cameraLDownwardRenderState 2 "ACTIVE" 1 "REQUESTED" 0 "INACTIVE" ;
VAL_ 1056 UIS_cameraLDownwardPacketState 2 "RECEIVING" 1 "MISSING" 0 "CHECKING" ;
VAL_ 1056 UIS_cameraFrontRenderState 2 "ACTIVE" 1 "REQUESTED" 0 "INACTIVE" ;
VAL_ 1056 UIS_cameraFrontPacketState 2 "RECEIVING" 1 "MISSING" 0 "CHECKING" ;
VAL_ 1056 UIS_cameraBackupStreamMissing 1 "MISSING" 0 "ACTIVE" ;
VAL_ 1056 UIS_cameraBackupRenderState 2 "ACTIVE" 1 "REQUESTED" 0 "INACTIVE" ;
VAL_ 1056 UIS_cameraBackupPopup 1 "OPEN" 0 "CLOSED" ;
VAL_ 1056 UIS_cameraBackupPipeline 4 "PLAYING" 3 "PAUSED" 2 "READY" 1 "NULL" 0 "SLEEP" ;
VAL_ 1056 UIS_cameraBackupPacketState 2 "RECEIVING" 1 "MISSING" 0 "CHECKING" ;
VAL_ 1056 UIS_bluetoothState 11 "CONNECTED" 10 "CONN_MAP" 9 "CONN_PBAP" 8 "CONN_A2DP" 7 "CONN_HFP" 6 "CONN_SPP" 5 "CONN_ACL" 4 "CONNECTING" 3 "PAIRING" 2 "DISCOVERY_STOP" 1 "DISCOVERY_START" 0 "DISCONNECTED" ;
VAL_ 1056 UIS_bluetoothStackState 4 "ON_BLUEZ" 3 "ON_SYNERGY" 2 "ON_LGIT" 1 "ON" 0 "OFF" ;
VAL_ 1056 UIS_bluetoothStackRearState 4 "ON_BLUEZ" 3 "ON_SYNERGY" 2 "ON_LGIT" 1 "ON" 0 "OFF" ;
VAL_ 1056 UIS_bluetoothPairResult 23 "HID_PAIRED" 22 "HID_MAX_NR_OF_CONNS" 21 "HID_PAGE_TIMEOUT" 20 "HID_OETC_USER" 19 "HID_REJ_BY_REMOTE_NO_RES" 18 "HID_LMP_RESPONSE_TIMEOUT" 17 "HID_AUTH_FAILURE" 16 "HID_KEY_MISSING" 15 "HID_NO_RESPONSE" 14 "HID_ALREADY_REQUESTED_BY_REMOTE" 13 "HID_UNKNOWN" 12 "HID_UNPAIRED" 11 "PAIRED" 10 "MAX_NR_OF_CONNS" 9 "PAGE_TIMEOUT" 8 "OETC_USER" 7 "REJ_BY_REMOTE_NO_RES" 6 "LMP_RESPONSE_TIMEOUT" 5 "AUTH_FAILURE" 4 "KEY_MISSING" 3 "NO_RESPONSE" 2 "ALREADY_REQUESTED_BY_REMOTE" 1 "UNKNOWN" 0 "UNPAIRED" ;
VAL_ 1056 UIS_bluetoothConnectionState 77 "HID_ERROR_UNKNOWN" 76 "HID_ERROR_ANTENNA_DISCONNECTED" 75 "HID_CONNECTED" 74 "HID_CONNECT_CANCELLED" 73 "HID_CONNECT_PROFILE_UNAVAILABLE" 72 "HID_CONNECT_INVALID_ARGUMENT" 71 "HID_CONNECT_ADAPTER_OFF" 70 "HID_CONNECT_NOT_SUPPORTED" 69 "HID_CONNECT_ALREADY_CONN" 68 "HID_CONNECT_DEVICE_NOT_FOUND_NO_RESOURCES" 67 "HID_CONNECT_DEVICE_NOT_FOUND_PAGE_TIMEOUT" 66 "HID_CONNECT_DEVICE_NOT_FOUND" 65 "HID_CONNECT_FAILED_REMOTE_TERMINATED" 64 "HID_CONNECT_FAILED_NO_RESOURCES" 63 "HID_CONNECT_FAILED_CONNECTION_TIMEOUT" 62 "HID_CONNECT_FAILED" 61 "HID_CONNECT_SDP_FAILURE" 60 "HID_CONNECT_PIN_MISSING" 59 "HID_CONNECT_PAGE_TIMEOUT" 58 "HID_CONNECT_REJ_BY_REMOTE_NO_RES" 57 "HID_CONNECT_MAX_NR_OF_CONNS" 56 "HID_CONNECT_CONTROLLER_BUSY" 55 "HID_CONNECT_CONN_TIMEOUT" 54 "HID_CONNECT_MAX_NR_OF_ACL" 53 "HID_CONNECT_LMP_RESPONSE_TIMEOUT" 52 "HID_CONNECT_HOST_TIMEOUT" 51 "HID_CONNECT_UNKNOWN_FAILURE" 50 "HID_DISCONNECT_UNKNOWN" 49 "HID_DISCONNECT_OETC_POWERING_OFF" 48 "HID_DISCONNECT_OETC_LOW_RESOURCE" 47 "HID_DISCONNECT_REJ_BY_REMOTE_SEC" 46 "HID_DISCONNECT_AUTH_FAIL" 45 "HID_DISCONNECT_LMP_RESPONSE_TIMEOUT" 44 "HID_DISCONNECT_OETC_USER" 43 "HID_DISCONNECT_CONN_TIMEOUT" 42 "HID_DISCONNECT_CONN_TERM_LOCAL_HOST" 41 "HID_DISCONNECT_LINKLOSS" 40 "HID_DISCONNECT_FROM_REMOTE" 39 "HID_DISCONNECTED" 38 "ERROR_UNKNOWN" 37 "ERROR_ANTENNA_DISCONNECTED" 36 "CONNECTED" 35 "CONNECT_CANCELLED" 34 "CONNECT_PROFILE_UNAVAILABLE" 33 "CONNECT_INVALID_ARGUMENT" 32 "CONNECT_ADAPTER_OFF" 31 "CONNECT_NOT_SUPPORTED" 30 "CONNECT_ALREADY_CONN" 29 "CONNECT_DEVICE_NOT_FOUND_NO_RESOURCES" 28 "CONNECT_DEVICE_NOT_FOUND_PAGE_TIMEOUT" 27 "CONNECT_DEVICE_NOT_FOUND" 26 "CONNECT_FAILED_REMOTE_TERMINATED" 25 "CONNECT_FAILED_NO_RESOURCES" 24 "CONNECT_FAILED_CONNECTION_TIMEOUT" 23 "CONNECT_FAILED" 22 "CONNECT_SDP_FAILURE" 21 "CONNECT_PIN_MISSING" 20 "CONNECT_PAGE_TIMEOUT" 19 "CONNECT_REJ_BY_REMOTE_NO_RES" 18 "CONNECT_MAX_NR_OF_CONNS" 17 "CONNECT_CONTROLLER_BUSY" 16 "CONNECT_CONN_TIMEOUT" 15 "CONNECT_MAX_NR_OF_ACL" 14 "CONNECT_LMP_RESPONSE_TIMEOUT" 13 "CONNECT_HOST_TIMEOUT" 12 "CONNECT_UNKNOWN_FAILURE" 11 "DISCONNECT_UNKNOWN" 10 "DISCONNECT_OETC_POWERING_OFF" 9 "DISCONNECT_OETC_LOW_RESOURCE" 8 "DISCONNECT_REJ_BY_REMOTE_SEC" 7 "DISCONNECT_AUTH_FAIL" 6 "DISCONNECT_LMP_RESPONSE_TIMEOUT" 5 "DISCONNECT_OETC_USER" 4 "DISCONNECT_CONN_TIMEOUT" 3 "DISCONNECT_CONN_TERM_LOCAL_HOST" 2 "DISCONNECT_LINKLOSS" 1 "DISCONNECT_FROM_REMOTE" 0 "DISCONNECTED" ;
VAL_ 1056 UIS_bluetoothAutoConnectionState 3 "MANUAL_CONNECT_REQUESTED" 2 "GAVE_UP" 1 "CONNECTED" 0 "IDLE" ;
VAL_ 1056 UIS_audioType 4 "BASE_WITH_PREMIUM200" 3 "PREMIUM" 2 "BASE" 1 "NO_A2B" 0 "INVALID" ;
VAL_ 1056 UIS_audioState 7 "SLEEPING" 6 "AUDIO_NOT_PUMPING" 5 "A2B_REDISCOVERY" 4 "HFP_PUMPING" 3 "AUDIO_PUMPING" 2 "UNINITIALIZING" 1 "INITIALIZING" 0 "TERMINATED" ;
VAL_ 1056 UIS_audioSource 5 "NONE" 4 "PHONE_RX" 3 "BLUETOOTH" 2 "MICROPHONE" 1 "TUNER" 0 "MEDIA" ;
VAL_ 1056 UIS_audioMediaPlaying 39 "SODA_MUSIC" 38 "CARAOKE" 37 "KUGOU" 36 "YOUTUBE_MUSIC" 35 "YUNTING" 34 "AMAZON_MUSIC" 33 "AUDIBLE" 32 "APPLE_PODCASTS" 31 "APPLE_MUSIC" 30 "MINI_PROGRAMS" 29 "SEARCH" 28 "HOME_APPS" 27 "RECENTS_FAVORITES" 26 "TOYBOX" 25 "TUTORIAL" 24 "THEATER" 23 "BROWSER" 22 "GAME" 21 "NET_EASE_MUSIC" 20 "ONLINE_RADIO" 19 "XIMALAYA" 18 "QQ_MUSIC2" 17 "QQ_MUSIC1" 16 "TIDAL" 15 "SIRIUS_XM" 14 "STINGRAY" 13 "TUNE_IN" 12 "EU_RADIO" 11 "US_RADIO" 10 "SPOTIFY" 9 "SLACKER" 8 "BLUETOOTH" 7 "USB" 6 "DAB" 5 "XM" 4 "FM" 3 "AM" 2 "UNKNOWN" 1 "DEPRECATED" 0 "NONE" ;
VAL_ 1056 UIS_audioMediaBrowsing 39 "SODA_MUSIC" 38 "CARAOKE" 37 "KUGOU" 36 "YOUTUBE_MUSIC" 35 "YUNTING" 34 "AMAZON_MUSIC" 33 "AUDIBLE" 32 "APPLE_PODCASTS" 31 "APPLE_MUSIC" 30 "MINI_PROGRAMS" 29 "SEARCH" 28 "HOME_APPS" 27 "RECENTS_FAVORITES" 26 "TOYBOX" 25 "TUTORIAL" 24 "THEATER" 23 "BROWSER" 22 "GAME" 21 "NET_EASE_MUSIC" 20 "ONLINE_RADIO" 19 "XIMALAYA" 18 "QQ_MUSIC2" 17 "QQ_MUSIC1" 16 "TIDAL" 15 "SIRIUS_XM" 14 "STINGRAY" 13 "TUNE_IN" 12 "EU_RADIO" 11 "US_RADIO" 10 "SPOTIFY" 9 "SLACKER" 8 "BLUETOOTH" 7 "USB" 6 "DAB" 5 "XM" 4 "FM" 3 "AM" 2 "UNKNOWN" 1 "DEPRECATED" 0 "NONE" ;
VAL_ 1056 UIS_activeAppView 67 "SODA_MUSIC" 66 "HICAR" 65 "CARAOKE_WEB" 64 "KUGOU" 63 "YOUTUBE_MUSIC" 62 "YUNTING" 61 "ONLINE_RADIO" 60 "AMAZON_MUSIC" 59 "AUDIBLE" 58 "APPLE_PODCASTS" 57 "ONBOARDING_MANUAL" 56 "APPLE_MUSIC" 55 "ZOOM" 54 "MINI_PROGRAMS" 53 "CADMIUM" 52 "MESSAGES" 51 "NAV_MEDIA" 50 "BACKGAMMON" 49 "SKETCH_PAD" 48 "ARCADE" 47 "XIMALAYA" 46 "BLUETOOTH" 45 "CHESS" 44 "NETEASE" 43 "OWNERS_MANUAL" 42 "QQMUSIC" 41 "RELEASE_NOTES" 40 "SONIC" 39 "USB" 38 "THEATER" 37 "TIDAL" 36 "TUNEIN" 35 "CARAOKE" 34 "STREAMING" 33 "RADIO" 32 "SPOTIFY" 31 "CAMERA" 30 "CHARGE" 29 "MEDIA" 28 "ENTERTAINMENT" 27 "WEB" 26 "CALENDAR" 25 "TOYBOX" 24 "PHONE" 23 "ENERGY" 22 "TUTORIAL" 21 "CERULEAN" 20 "TOPAZ" 19 "DASHCAM" 18 "CARBONADO" 17 "THEATERVIEW" 16 "MAMBU" 15 "COBALT" 14 "TESLATARI" 13 "SERVICE_APPS" 12 "LIME" 11 "TEARDROP" 10 "NAV" 9 "PURPLE" 8 "CALICO" 7 "CARWASH" 6 "2048" 5 "CONTROLS" 4 "COLORIZER" 3 "XM" 2 "DEVELOPMENT" 1 "NONE" 0 "UNKNOWN" ;
VAL_ 979 UI_airbagCutoffSwState 2 "SNA" 1 "PASSENGER_AIRBAG_OFF" 0 "PASSENGER_AIRBAG_ON" ;
VAL_ 1279 UI_energyConsumptionInfoIndex 21 "21" 20 "20" 19 "19" 18 "18" 17 "17" 16 "16" 15 "15" 14 "14" 13 "13" 12 "12" 11 "11" 10 "10" 9 "9" 8 "8" 7 "7" 6 "6" 5 "5" 4 "4" 3 "3" 2 "2" 1 "1" 0 "0" ;
VAL_ 666 UI_seatControlIndex 3 "3" 2 "2" 1 "1" 0 "0" ;
VAL_ 666 UI_3RSeatChildLock 3 "UI_ADJUSTABLE_FOLD_FLAT_CHILD_LOCK_BOTH" 2 "UI_ADJUSTABLE_FOLD_FLAT_CHILD_LOCK_RIGHT" 1 "UI_ADJUSTABLE_FOLD_FLAT_CHILD_LOCK_LEFT" 0 "UI_ADJUSTABLE_FOLD_FLAT_CHILD_LOCK_NONE" ;
VAL_ 666 UI_left3RowSeatAdjustmentRequest 6 "UI_ADJUSTABLE_FOLD_FLAT_REQUEST_STOP" 5 "UI_ADJUSTABLE_FOLD_FLAT_REQUEST_TOGGLE_FOLD" 4 "UI_ADJUSTABLE_FOLD_FLAT_REQUEST_REARWARD_FAST" 3 "UI_ADJUSTABLE_FOLD_FLAT_REQUEST_REARWARD_COMFORT" 2 "UI_ADJUSTABLE_FOLD_FLAT_REQUEST_FORWARD_FAST" 1 "UI_ADJUSTABLE_FOLD_FLAT_REQUEST_FORWARD_COMFORT" 0 "UI_ADJUSTABLE_FOLD_FLAT_REQUEST_NONE" ;
VAL_ 666 UI_right3RowSeatAdjustmentReques 6 "UI_ADJUSTABLE_FOLD_FLAT_REQUEST_STOP" 5 "UI_ADJUSTABLE_FOLD_FLAT_REQUEST_TOGGLE_FOLD" 4 "UI_ADJUSTABLE_FOLD_FLAT_REQUEST_REARWARD_FAST" 3 "UI_ADJUSTABLE_FOLD_FLAT_REQUEST_REARWARD_COMFORT" 2 "UI_ADJUSTABLE_FOLD_FLAT_REQUEST_FORWARD_FAST" 1 "UI_ADJUSTABLE_FOLD_FLAT_REQUEST_FORWARD_COMFORT" 0 "UI_ADJUSTABLE_FOLD_FLAT_REQUEST_NONE" ;
VAL_ 666 UI_2RLeftSeatFanReq 3 "FAN_REQUEST_LEVEL3" 2 "FAN_REQUEST_LEVEL2" 1 "FAN_REQUEST_LEVEL1" 0 "FAN_REQUEST_OFF" ;
VAL_ 666 UI_2RRightSeatFanReq 3 "FAN_REQUEST_LEVEL3" 2 "FAN_REQUEST_LEVEL2" 1 "FAN_REQUEST_LEVEL1" 0 "FAN_REQUEST_OFF" ;
VAL_ 563 UI_gearRequest 4 "GEAR_REQUEST_DRIVE" 3 "GEAR_REQUEST_NEUTRAL" 2 "GEAR_REQUEST_REVERSE" 1 "GEAR_REQUEST_PARK" 0 "GEAR_REQUEST_IDLE_SNA" ;
VAL_ 986 UI_wifiRegDomain 67 "AZ" 66 "SR" 65 "SM" 64 "MS" 63 "MT" 62 "LV" 61 "LT" 60 "LI" 59 "GI" 58 "CY" 57 "AD" 56 "PT" 55 "MU" 54 "LU" 53 "EE" 52 "BG" 51 "BR" 50 "IN" 49 "IE" 48 "IS" 47 "AE" 46 "TR" 45 "ES" 44 "SI" 43 "SK" 42 "RO" 41 "PR" 40 "PL" 39 "HU" 38 "GR" 37 "FI" 36 "HR" 35 "CZ" 34 "NZ" 33 "MO" 32 "SA" 31 "PH" 30 "CO" 29 "QA" 28 "CL" 27 "MY" 26 "TH" 25 "SG" 24 "JO" 23 "MX" 22 "TW" 21 "KR" 20 "RU" 19 "GB" 18 "IL" 17 "AU" 16 "JP" 15 "HK" 14 "CN" 13 "UK" 12 "SE" 11 "CH" 10 "NO" 9 "DK" 8 "BE" 7 "AT" 6 "NL" 5 "IT" 4 "FR" 3 "DE" 2 "CA" 1 "US" 0 "UNKNOWN" ;
VAL_ 661 UI_systemMonitorIndex 1 "1" 0 "0" ;
VAL_ 139 UI_maxSpeedToReachDestination 65535 "SNA" 65534 "UNREACHABLE" 65533 "MAXVAL" ;
VAL_ 139 UI_timeToDestination 65535 "SNA" 65534 "MAXVAL" ;
VAL_ 1173 UI_predictedEnergy -32767 "TRIP_TOO_LONG" -32768 "SNA" ;
VAL_ 1173 UI_hindsightEnergy -32767 "TRIP_TOO_LONG" -32768 "SNA" ;
VAL_ 764 VCSEAT2L_row2SeatStatusIndex 3 "ARMREST" 2 "ADJUSTABLE_FOLD_FLAT" 1 "POSITION" 0 "TRACK" ;
VAL_ 764 VCSEAT2L_seatReclineState 15 "SEAT_ADJUSTABLE_FOLD_FLAT_STATE_SNA" 12 "SEAT_ADJUSTABLE_FOLD_FLAT_STATE_CALIBRATING_ABSOLUTE_SENSOR" 11 "SEAT_ADJUSTABLE_FOLD_FLAT_STATE_CALIBRATING_ZERO_POSITION" 10 "SEAT_ADJUSTABLE_FOLD_FLAT_STATE_WAITING_TO_CLEAR_FOR_UNFOLD" 9 "SEAT_ADJUSTABLE_FOLD_FLAT_STATE_WAITING_TO_CLEAR_FOR_FOLD" 8 "SEAT_ADJUSTABLE_FOLD_FLAT_STATE_MOVING_REARWARD_TO_POSITION" 7 "SEAT_ADJUSTABLE_FOLD_FLAT_STATE_MOVING_FORWARD_TO_POSITION" 6 "SEAT_ADJUSTABLE_FOLD_FLAT_STATE_UNFOLDING" 5 "SEAT_ADJUSTABLE_FOLD_FLAT_STATE_FOLDING" 4 "SEAT_ADJUSTABLE_FOLD_FLAT_STATE_ADJUSTING_REARWARD_FAST" 3 "SEAT_ADJUSTABLE_FOLD_FLAT_STATE_ADJUSTING_FORWARD_FAST" 2 "SEAT_ADJUSTABLE_FOLD_FLAT_STATE_ADJUSTING_REARWARD_COMFORT" 1 "SEAT_ADJUSTABLE_FOLD_FLAT_STATE_ADJUSTING_FORWARD_COMFORT" 0 "SEAT_ADJUSTABLE_FOLD_FLAT_STATE_STOPPED" ;
VAL_ 764 VCSEAT2L_seatReclinePositionStat 4 "SEAT_ADJUSTABLE_FOLD_FLAT_POSITION_STATE_SNA" 3 "SEAT_ADJUSTABLE_FOLD_FLAT_POSITION_STATE_UNKNOWN" 2 "SEAT_ADJUSTABLE_FOLD_FLAT_POSITION_STATE_UNSAFE_INTERMEDIATE" 1 "SEAT_ADJUSTABLE_FOLD_FLAT_POSITION_STATE_UNFOLDED" 0 "SEAT_ADJUSTABLE_FOLD_FLAT_POSITION_STATE_FOLDED" ;
VAL_ 764 VCSEAT2L_seatReclineAbsPosSwitch 3 "SWITCH_FAULT" 2 "SWITCH_ON" 1 "SWITCH_OFF" 0 "SWITCH_SNA" ;
VAL_ 764 VCSEAT2L_seat1RClashAvoidanceBlo 6 "SEAT_FOLD_FLAT_CLASH_AVOIDANCE_REASON_FRONT_SEAT_OCCUPANCY" 5 "SEAT_FOLD_FLAT_CLASH_AVOIDANCE_REASON_FRONT_SEAT_MOVING" 4 "SEAT_FOLD_FLAT_CLASH_AVOIDANCE_REASON_FRONT_SEAT_PROFILE_RECALL" 3 "SEAT_FOLD_FLAT_CLASH_AVOIDANCE_REASON_REAR_SEAT_UNCALIBRATED" 2 "SEAT_FOLD_FLAT_CLASH_AVOIDANCE_REASON_FRONT_SEAT_UNCALIBRATED" 1 "SEAT_FOLD_FLAT_CLASH_AVOIDANCE_REASON_VEHICLE_IN_MOTION" 0 "SEAT_FOLD_FLAT_CLASH_AVOIDANCE_REASON_NONE" ;
VAL_ 764 VCSEAT2L_seat1RClashAvoidanceSta 3 "SEAT_FOLD_FLAT_CLASH_AVOIDANCE_STATE_RESTORING_FRONT_SEAT" 2 "SEAT_FOLD_FLAT_CLASH_AVOIDANCE_STATE_WAITING_TO_RESTORE_FRONT_SEAT" 1 "SEAT_FOLD_FLAT_CLASH_AVOIDANCE_STATE_FRONT_SEAT_CLEARING" 0 "SEAT_FOLD_FLAT_CLASH_AVOIDANCE_STATE_IDLE" ;
VAL_ 764 VCSEAT2L_seatReclineNextToggleDi 2 "SEAT_ADJUSTABLE_FOLD_FLAT_NEXT_TOGGLE_DIRECTION_SNA" 1 "SEAT_ADJUSTABLE_FOLD_FLAT_NEXT_TOGGLE_DIRECTION_UNFOLD" 0 "SEAT_ADJUSTABLE_FOLD_FLAT_NEXT_TOGGLE_DIRECTION_FOLD" ;
VAL_ 1986 VCSEAT2L_seatStatus2Index 5 "LOADSHED" 4 "CHOREOGRAPHY" 3 "VENTILATION" 2 "OCCUPANCY" 1 "SEAT_VOLTAGES" 0 "SEAT_HEAT_FRONT" ;
VAL_ 1986 VCSEAT2L_choreography2RState 2 "SEAT_CHOREOGRAPHY_ROW_STATE_UNFOLDING" 1 "SEAT_CHOREOGRAPHY_ROW_STATE_FOLDING" 0 "SEAT_CHOREOGRAPHY_ROW_STATE_IDLE" ;
VAL_ 1986 VCSEAT2L_choreography3RState 2 "SEAT_CHOREOGRAPHY_ROW_STATE_UNFOLDING" 1 "SEAT_CHOREOGRAPHY_ROW_STATE_FOLDING" 0 "SEAT_CHOREOGRAPHY_ROW_STATE_IDLE" ;
VAL_ 1986 VCSEAT2L_choreography1RTrackVelo 6 "SEAT_MOTOR_VELOCITY_TYPE_HIGH_BACKWARD" 5 "SEAT_MOTOR_VELOCITY_TYPE_HIGH_FORWARD" 4 "SEAT_MOTOR_VELOCITY_TYPE_MID_BACKWARD" 3 "SEAT_MOTOR_VELOCITY_TYPE_MID_FORWARD" 2 "SEAT_MOTOR_VELOCITY_TYPE_LOW_BACKWARD" 1 "SEAT_MOTOR_VELOCITY_TYPE_LOW_FORWARD" 0 "SEAT_MOTOR_VELOCITY_TYPE_STOP" ;
VAL_ 1986 VCSEAT2L_choreography1RBackrestV 6 "SEAT_MOTOR_VELOCITY_TYPE_HIGH_BACKWARD" 5 "SEAT_MOTOR_VELOCITY_TYPE_HIGH_FORWARD" 4 "SEAT_MOTOR_VELOCITY_TYPE_MID_BACKWARD" 3 "SEAT_MOTOR_VELOCITY_TYPE_MID_FORWARD" 2 "SEAT_MOTOR_VELOCITY_TYPE_LOW_BACKWARD" 1 "SEAT_MOTOR_VELOCITY_TYPE_LOW_FORWARD" 0 "SEAT_MOTOR_VELOCITY_TYPE_STOP" ;
VAL_ 1986 VCSEAT2L_choreography2RTrackVelo 6 "SEAT_MOTOR_VELOCITY_TYPE_HIGH_BACKWARD" 5 "SEAT_MOTOR_VELOCITY_TYPE_HIGH_FORWARD" 4 "SEAT_MOTOR_VELOCITY_TYPE_MID_BACKWARD" 3 "SEAT_MOTOR_VELOCITY_TYPE_MID_FORWARD" 2 "SEAT_MOTOR_VELOCITY_TYPE_LOW_BACKWARD" 1 "SEAT_MOTOR_VELOCITY_TYPE_LOW_FORWARD" 0 "SEAT_MOTOR_VELOCITY_TYPE_STOP" ;
VAL_ 1986 VCSEAT2L_choreography2RBackrestV 6 "SEAT_MOTOR_VELOCITY_TYPE_HIGH_BACKWARD" 5 "SEAT_MOTOR_VELOCITY_TYPE_HIGH_FORWARD" 4 "SEAT_MOTOR_VELOCITY_TYPE_MID_BACKWARD" 3 "SEAT_MOTOR_VELOCITY_TYPE_MID_FORWARD" 2 "SEAT_MOTOR_VELOCITY_TYPE_LOW_BACKWARD" 1 "SEAT_MOTOR_VELOCITY_TYPE_LOW_FORWARD" 0 "SEAT_MOTOR_VELOCITY_TYPE_STOP" ;
VAL_ 1986 VCSEAT2L_choreography3RBackrestV 6 "SEAT_MOTOR_VELOCITY_TYPE_HIGH_BACKWARD" 5 "SEAT_MOTOR_VELOCITY_TYPE_HIGH_FORWARD" 4 "SEAT_MOTOR_VELOCITY_TYPE_MID_BACKWARD" 3 "SEAT_MOTOR_VELOCITY_TYPE_MID_FORWARD" 2 "SEAT_MOTOR_VELOCITY_TYPE_LOW_BACKWARD" 1 "SEAT_MOTOR_VELOCITY_TYPE_LOW_FORWARD" 0 "SEAT_MOTOR_VELOCITY_TYPE_STOP" ;
VAL_ 1986 VCSEAT2L_choreographyState 10 "SEAT_CHOREO_STATE_1R_RESTORE" 9 "SEAT_CHOREO_STATE_1R_CLEAR_2R_MID_OUT_OF_KEEPOUT_ZONE_3R_MID" 8 "SEAT_CHOREO_STATE_1R_CLEAR_2R_FAST_OUT_OF_KEEPOUT_ZONE_3R_MID" 7 "SEAT_CHOREO_STATE_1R_STOP_2R_FAST_OUT_OF_KEEPOUT_ZONE_3R_MID" 6 "SEAT_CHOREO_STATE_1R_STOP_2R_FAST_OUT_OF_KEEPOUT_ZONE_3R_FAST" 5 "SEAT_CHOREO_STATE_2R_STOP_3R_FAST" 4 "SEAT_CHOREO_STATE_1R_CLEAR_2R_STOP_OUT_OF_KEEPOUT_ZONE" 3 "SEAT_CHOREO_STATE_1R_CLEAR_2R_MID_OUT_OF_KEEPOUT_ZONE" 2 "SEAT_CHOREO_STATE_1R_CLEAR_2R_FAST_OUT_OF_KEEPOUT_ZONE" 1 "SEAT_CHOREO_STATE_1R_STOP_2R_FAST_OUT_OF_KEEPOUT_ZONE" 0 "SEAT_CHOREO_STATE_INVALID" ;
VAL_ 1986 VCSEAT2L_choreographyCollisionPa 4 "SEAT_CHOREOGRAPHY_COLLISION_PAIR_2R_BACKREST_3R_BACKREST" 3 "SEAT_CHOREOGRAPHY_COLLISION_PAIR_2R_CUSHION_3R_BACKREST" 2 "SEAT_CHOREOGRAPHY_COLLISION_PAIR_1R_BACKREST_2R_BACKREST" 1 "SEAT_CHOREOGRAPHY_COLLISION_PAIR_1R_BACKREST_2R_CUSHION" 0 "SEAT_CHOREOGRAPHY_COLLISION_PAIR_NONE" ;
VAL_ 746 VCSEAT2R_seatStatus2Index 5 "LOADSHED" 4 "CHOREOGRAPHY" 3 "VENTILATION" 2 "OCCUPANCY" 1 "SEAT_VOLTAGES" 0 "SEAT_HEAT_FRONT" ;
VAL_ 746 VCSEAT2R_choreography2RState 2 "SEAT_CHOREOGRAPHY_ROW_STATE_UNFOLDING" 1 "SEAT_CHOREOGRAPHY_ROW_STATE_FOLDING" 0 "SEAT_CHOREOGRAPHY_ROW_STATE_IDLE" ;
VAL_ 746 VCSEAT2R_choreography3RState 2 "SEAT_CHOREOGRAPHY_ROW_STATE_UNFOLDING" 1 "SEAT_CHOREOGRAPHY_ROW_STATE_FOLDING" 0 "SEAT_CHOREOGRAPHY_ROW_STATE_IDLE" ;
VAL_ 746 VCSEAT2R_choreography1RTrackVelo 6 "SEAT_MOTOR_VELOCITY_TYPE_HIGH_BACKWARD" 5 "SEAT_MOTOR_VELOCITY_TYPE_HIGH_FORWARD" 4 "SEAT_MOTOR_VELOCITY_TYPE_MID_BACKWARD" 3 "SEAT_MOTOR_VELOCITY_TYPE_MID_FORWARD" 2 "SEAT_MOTOR_VELOCITY_TYPE_LOW_BACKWARD" 1 "SEAT_MOTOR_VELOCITY_TYPE_LOW_FORWARD" 0 "SEAT_MOTOR_VELOCITY_TYPE_STOP" ;
VAL_ 746 VCSEAT2R_choreography1RBackrestV 6 "SEAT_MOTOR_VELOCITY_TYPE_HIGH_BACKWARD" 5 "SEAT_MOTOR_VELOCITY_TYPE_HIGH_FORWARD" 4 "SEAT_MOTOR_VELOCITY_TYPE_MID_BACKWARD" 3 "SEAT_MOTOR_VELOCITY_TYPE_MID_FORWARD" 2 "SEAT_MOTOR_VELOCITY_TYPE_LOW_BACKWARD" 1 "SEAT_MOTOR_VELOCITY_TYPE_LOW_FORWARD" 0 "SEAT_MOTOR_VELOCITY_TYPE_STOP" ;
VAL_ 746 VCSEAT2R_choreography2RTrackVelo 6 "SEAT_MOTOR_VELOCITY_TYPE_HIGH_BACKWARD" 5 "SEAT_MOTOR_VELOCITY_TYPE_HIGH_FORWARD" 4 "SEAT_MOTOR_VELOCITY_TYPE_MID_BACKWARD" 3 "SEAT_MOTOR_VELOCITY_TYPE_MID_FORWARD" 2 "SEAT_MOTOR_VELOCITY_TYPE_LOW_BACKWARD" 1 "SEAT_MOTOR_VELOCITY_TYPE_LOW_FORWARD" 0 "SEAT_MOTOR_VELOCITY_TYPE_STOP" ;
VAL_ 746 VCSEAT2R_choreography2RBackrestV 6 "SEAT_MOTOR_VELOCITY_TYPE_HIGH_BACKWARD" 5 "SEAT_MOTOR_VELOCITY_TYPE_HIGH_FORWARD" 4 "SEAT_MOTOR_VELOCITY_TYPE_MID_BACKWARD" 3 "SEAT_MOTOR_VELOCITY_TYPE_MID_FORWARD" 2 "SEAT_MOTOR_VELOCITY_TYPE_LOW_BACKWARD" 1 "SEAT_MOTOR_VELOCITY_TYPE_LOW_FORWARD" 0 "SEAT_MOTOR_VELOCITY_TYPE_STOP" ;
VAL_ 746 VCSEAT2R_choreography3RBackrestV 6 "SEAT_MOTOR_VELOCITY_TYPE_HIGH_BACKWARD" 5 "SEAT_MOTOR_VELOCITY_TYPE_HIGH_FORWARD" 4 "SEAT_MOTOR_VELOCITY_TYPE_MID_BACKWARD" 3 "SEAT_MOTOR_VELOCITY_TYPE_MID_FORWARD" 2 "SEAT_MOTOR_VELOCITY_TYPE_LOW_BACKWARD" 1 "SEAT_MOTOR_VELOCITY_TYPE_LOW_FORWARD" 0 "SEAT_MOTOR_VELOCITY_TYPE_STOP" ;
VAL_ 746 VCSEAT2R_choreographyState 10 "SEAT_CHOREO_STATE_1R_RESTORE" 9 "SEAT_CHOREO_STATE_1R_CLEAR_2R_MID_OUT_OF_KEEPOUT_ZONE_3R_MID" 8 "SEAT_CHOREO_STATE_1R_CLEAR_2R_FAST_OUT_OF_KEEPOUT_ZONE_3R_MID" 7 "SEAT_CHOREO_STATE_1R_STOP_2R_FAST_OUT_OF_KEEPOUT_ZONE_3R_MID" 6 "SEAT_CHOREO_STATE_1R_STOP_2R_FAST_OUT_OF_KEEPOUT_ZONE_3R_FAST" 5 "SEAT_CHOREO_STATE_2R_STOP_3R_FAST" 4 "SEAT_CHOREO_STATE_1R_CLEAR_2R_STOP_OUT_OF_KEEPOUT_ZONE" 3 "SEAT_CHOREO_STATE_1R_CLEAR_2R_MID_OUT_OF_KEEPOUT_ZONE" 2 "SEAT_CHOREO_STATE_1R_CLEAR_2R_FAST_OUT_OF_KEEPOUT_ZONE" 1 "SEAT_CHOREO_STATE_1R_STOP_2R_FAST_OUT_OF_KEEPOUT_ZONE" 0 "SEAT_CHOREO_STATE_INVALID" ;
VAL_ 746 VCSEAT2R_choreographyCollisionPa 4 "SEAT_CHOREOGRAPHY_COLLISION_PAIR_2R_BACKREST_3R_BACKREST" 3 "SEAT_CHOREOGRAPHY_COLLISION_PAIR_2R_CUSHION_3R_BACKREST" 2 "SEAT_CHOREOGRAPHY_COLLISION_PAIR_1R_BACKREST_2R_BACKREST" 1 "SEAT_CHOREOGRAPHY_COLLISION_PAIR_1R_BACKREST_2R_CUSHION" 0 "SEAT_CHOREOGRAPHY_COLLISION_PAIR_NONE" ;
